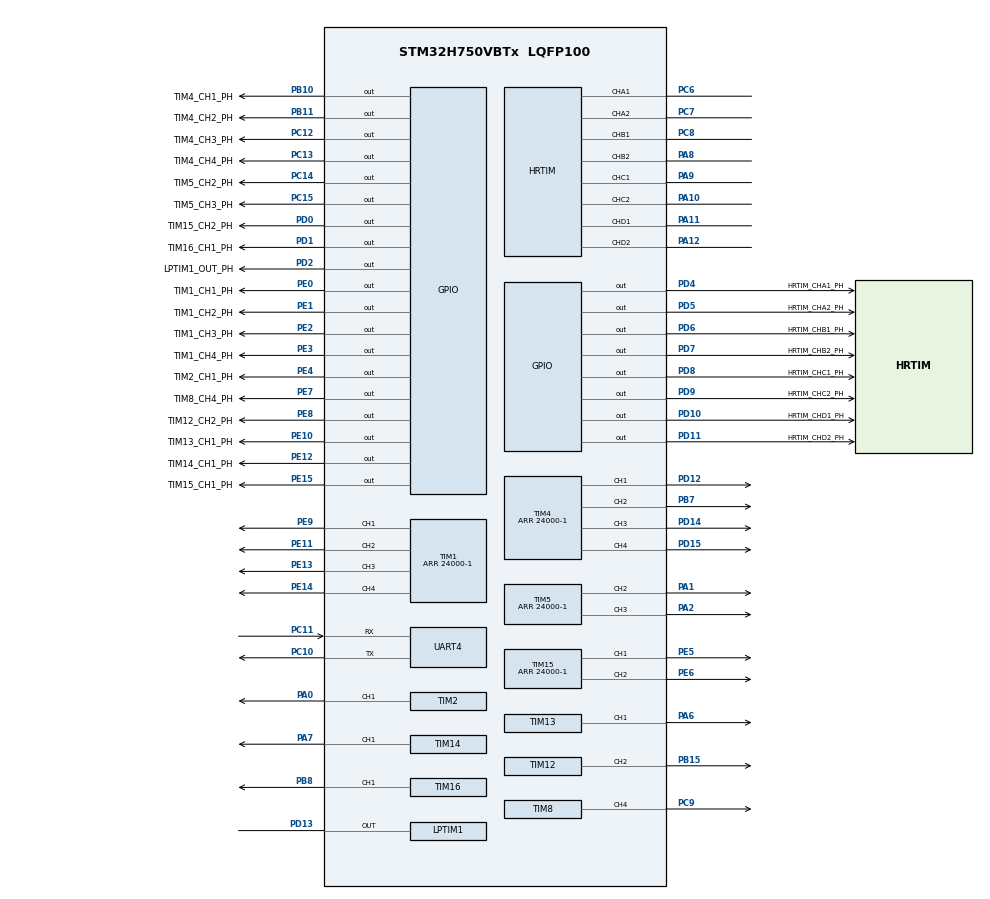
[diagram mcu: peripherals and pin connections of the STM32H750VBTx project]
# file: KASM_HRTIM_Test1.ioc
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CORTEX_M7.default_mode_Activation=1
HRTIM.CaptureUnit1-Output_TA1TA2=__NULL
HRTIM.CompareUnit1-Output_TA1TA2=HRTIM_COMPAREUNIT_1
HRTIM.CompareUnit1-Output_TB1TB2=HRTIM_COMPAREUNIT_1
HRTIM.CompareUnit1-Output_TC1TC2=HRTIM_COMPAREUNIT_1
HRTIM.CompareUnit1-Output_TD1TD2=HRTIM_COMPAREUNIT_1
HRTIM.CompareUnit2-Output_TA1TA2=HRTIM_COMPAREUNIT_2
HRTIM.CompareUnit2-Output_TB1TB2=HRTIM_COMPAREUNIT_2
HRTIM.CompareUnit2-Output_TC1TC2=HRTIM_COMPAREUNIT_2
HRTIM.CompareUnit2-Output_TD1TD2=HRTIM_COMPAREUNIT_2
HRTIM.CompareValue1-Output_TA1TA2=0x00005A00/2
HRTIM.CompareValue1-Output_TB1TB2=0x00005A00/2
HRTIM.CompareValue1-Output_TC1TC2=0x00005A00/2
HRTIM.CompareValue1-Output_TD1TD2=0x00005A00/2
HRTIM.CompareValue2-Output_TA1TA2=0x00005A00/2
HRTIM.CompareValue2-Output_TB1TB2=0x00005A00/2
HRTIM.CompareValue2-Output_TC1TC2=0x00005A00/2
HRTIM.CompareValue2-Output_TD1TD2=0x00005A00/2
HRTIM.Configuration_TA=Waveform
HRTIM.Enable=HRTIM_BURSTMODECTL_DISABLED
HRTIM.Event1-Output_TA1TA2=__NULL
HRTIM.Event_EEV1=HRTIM_EVENT_1
HRTIM.Event_EEV2=__NULL
HRTIM.HalfModeEnable-Output_TA1TA2=HRTIM_HALFMODE_DISABLED
HRTIM.NumberResetSource1-Output_TA1TA2=1
HRTIM.NumberResetSource1-Output_TB1TB2=1
HRTIM.NumberResetSource1-Output_TC1TC2=1
HRTIM.NumberResetSource1-Output_TD1TD2=1
HRTIM.NumberResetSource2_TA=1
HRTIM.NumberResetSource2_TB=1
HRTIM.NumberResetSource2_TC=1
HRTIM.NumberResetSource2_TD=1
HRTIM.NumberResetTrigger-Output_TA1TA2=1
HRTIM.NumberResetTrigger-Output_TB1TB2=1
HRTIM.NumberResetTrigger-Output_TC1TC2=1
HRTIM.NumberResetTrigger-Output_TD1TD2=1
HRTIM.NumberSetSource1-Output_TA1TA2=2
HRTIM.NumberSetSource1-Output_TB1TB2=2
HRTIM.NumberSetSource1-Output_TC1TC2=2
HRTIM.NumberSetSource1-Output_TD1TD2=2
HRTIM.NumberSetSource2_TA=2
HRTIM.NumberSetSource2_TB=2
HRTIM.NumberSetSource2_TC=2
HRTIM.NumberSetSource2_TD=2
HRTIM.NumberUpdateTrigger-Output_TA1TA2=0
HRTIM.Periode_TA=24000-1
HRTIM.Periode_TB=24000-1
HRTIM.Periode_TC=24000-1
HRTIM.Periode_TD=24000-1
HRTIM.Polarity1-Output_TA1TA2=HRTIM_OUTPUTPOLARITY_HIGH
HRTIM.PreloadEnable-Output_TA1TA2=HRTIM_PRELOAD_ENABLED
HRTIM.PreloadEnable-Output_TB1TB2=HRTIM_PRELOAD_ENABLED
HRTIM.PreloadEnable-Output_TC1TC2=HRTIM_PRELOAD_ENABLED
HRTIM.PreloadEnable-Output_TD1TD2=HRTIM_PRELOAD_ENABLED
HRTIM.PrescalerRatio_TA=HRTIM_PRESCALERRATIO_DIV1
HRTIM.PushPull-Output_TA1TA2=HRTIM_TIMPUSHPULLMODE_DISABLED
HRTIM.PushPull-Output_TB1TB2=HRTIM_TIMPUSHPULLMODE_DISABLED
HRTIM.RepetitionUpdate-Output_TA1TA2=HRTIM_UPDATEONREPETITION_DISABLED
HRTIM.ResetOutput1_Source1-Output_TA1TA2=HRTIM_OUTPUTRESET_TIMCMP1
HRTIM.ResetOutput1_Source1-Output_TB1TB2=HRTIM_OUTPUTRESET_TIMCMP1
HRTIM.ResetOutput1_Source1-Output_TC1TC2=HRTIM_OUTPUTRESET_TIMCMP1
HRTIM.ResetOutput1_Source1-Output_TD1TD2=HRTIM_OUTPUTRESET_TIMCMP1
HRTIM.ResetOutput2_Source1-Output_TA1TA2=HRTIM_OUTPUTRESET_TIMCMP2
HRTIM.ResetOutput2_Source1-Output_TB1TB2=HRTIM_OUTPUTRESET_TIMCMP2
HRTIM.ResetOutput2_Source1-Output_TC1TC2=HRTIM_OUTPUTRESET_TIMCMP2
HRTIM.ResetOutput2_Source1-Output_TD1TD2=HRTIM_OUTPUTRESET_TIMCMP2
HRTIM.ResetTrigger1-Output_TA1TA2=HRTIM_TIMRESETTRIGGER_EEV_1
HRTIM.ResetTrigger1-Output_TB1TB2=HRTIM_TIMRESETTRIGGER_EEV_1
HRTIM.ResetTrigger1-Output_TC1TC2=HRTIM_TIMRESETTRIGGER_EEV_1
HRTIM.ResetTrigger1-Output_TD1TD2=HRTIM_TIMRESETTRIGGER_EEV_1
HRTIM.ResetUpdate-Output_TA1TA2=HRTIM_TIMUPDATEONRESET_ENABLED
HRTIM.ResetUpdate-Output_TB1TB2=HRTIM_TIMUPDATEONRESET_ENABLED
HRTIM.ResetUpdate-Output_TC1TC2=HRTIM_TIMUPDATEONRESET_ENABLED
HRTIM.ResetUpdate-Output_TD1TD2=HRTIM_TIMUPDATEONRESET_ENABLED
HRTIM.Sensitivity_EEV1=HRTIM_EVENTSENSITIVITY_RISINGEDGE
HRTIM.SetOutput1_Source1-Output_TA1TA2=HRTIM_OUTPUTSET_EEV_1
HRTIM.SetOutput1_Source1-Output_TB1TB2=HRTIM_OUTPUTSET_EEV_1
HRTIM.SetOutput1_Source1-Output_TC1TC2=HRTIM_OUTPUTSET_EEV_1
HRTIM.SetOutput1_Source1-Output_TD1TD2=HRTIM_OUTPUTSET_EEV_1
HRTIM.SetOutput1_Source2-Output_TA1TA2=HRTIM_OUTPUTSET_TIMPER
HRTIM.SetOutput1_Source2-Output_TB1TB2=HRTIM_OUTPUTSET_TIMPER
HRTIM.SetOutput1_Source2-Output_TC1TC2=HRTIM_OUTPUTSET_TIMPER
HRTIM.SetOutput1_Source2-Output_TD1TD2=HRTIM_OUTPUTSET_TIMPER
HRTIM.SetOutput2_Source1-Output_TA1TA2=HRTIM_OUTPUTSET_EEV_1
HRTIM.SetOutput2_Source1-Output_TB1TB2=HRTIM_OUTPUTSET_EEV_1
HRTIM.SetOutput2_Source1-Output_TC1TC2=HRTIM_OUTPUTSET_EEV_1
HRTIM.SetOutput2_Source1-Output_TD1TD2=HRTIM_OUTPUTSET_EEV_1
HRTIM.SetOutput2_Source2-Output_TA1TA2=HRTIM_OUTPUTSET_TIMPER
HRTIM.SetOutput2_Source2-Output_TB1TB2=HRTIM_OUTPUTSET_TIMPER
HRTIM.SetOutput2_Source2-Output_TC1TC2=HRTIM_OUTPUTSET_TIMPER
HRTIM.SetOutput2_Source2-Output_TD1TD2=HRTIM_OUTPUTSET_TIMPER
HRTIM.Source_EEV1=HRTIM_EVENTSRC_3
HRTIM.StartOnSync-Output_TA1TA2=HRTIM_SYNCSTART_DISABLED
HRTIM.SyncOptions=HRTIM_SYNCOPTION_NONE
LPTIM1.OutputPolarity=LPTIM_OUTPUTPOLARITY_LOW
LPTIM1.TriggerSource=LPTIM_TRIGSOURCE_SOFTWARE
LPTIM1.UpdateMode=LPTIM_UPDATE_IMMEDIATE
Mcu.Family=STM32H7
Mcu.Name=STM32H750VBTx
Mcu.Package=LQFP100
NVIC.LPTIM1_IRQn=true\:0\:0\:false\:false\:true\:true\:true\:true
NVIC.PriorityGroup=NVIC_PRIORITYGROUP_4
NVIC.TIM15_IRQn=true\:0\:0\:false\:false\:true\:true\:true\:true
NVIC.TIM16_IRQn=true\:0\:0\:false\:false\:true\:true\:true\:true
NVIC.TIM1_UP_IRQn=true\:0\:0\:false\:false\:true\:true\:true\:true
NVIC.TIM2_IRQn=true\:0\:0\:false\:false\:true\:true\:true\:true
NVIC.TIM4_IRQn=true\:0\:0\:false\:false\:true\:true\:true\:true
NVIC.TIM5_IRQn=true\:0\:0\:false\:false\:true\:true\:true\:true
NVIC.TIM8_BRK_TIM12_IRQn=true\:0\:0\:false\:false\:true\:true\:true\:true
NVIC.TIM8_TRG_COM_TIM14_IRQn=true\:0\:0\:false\:false\:true\:true\:true\:true
NVIC.TIM8_UP_TIM13_IRQn=true\:0\:0\:false\:false\:true\:true\:true\:true
NVIC.UART4_IRQn=true\:0\:0\:false\:false\:true\:true\:true\:true
PA0.Signal=S_TIM2_CH1_ETR
PA1.Signal=S_TIM5_CH2
PA10.Mode=Output_TC1TC2
PA10.Signal=HRTIM_CHC2
PA11.Mode=Output_TD1TD2
PA11.Signal=HRTIM_CHD1
PA12.Mode=Output_TD1TD2
PA12.Signal=HRTIM_CHD2
PA2.Signal=S_TIM5_CH3
PA6.Signal=S_TIM13_CH1
PA7.Signal=S_TIM14_CH1
PA8.Mode=Output_TB1TB2
PA8.Signal=HRTIM_CHB2
PA9.Mode=Output_TC1TC2
PA9.Signal=HRTIM_CHC1
PB10.GPIO_Label=TIM4_CH1_PH
PB10.Signal=GPIO_Output
PB11.GPIO_Label=TIM4_CH2_PH
PB11.Signal=GPIO_Output
PB15.Signal=S_TIM12_CH2
PB7.Signal=S_TIM4_CH2
PB8.Signal=S_TIM16_CH1
PC10.Mode=Asynchronous
PC10.Signal=UART4_TX
PC11.Mode=Asynchronous
PC11.Signal=UART4_RX
PC12.GPIO_Label=TIM4_CH3_PH
PC12.Signal=GPIO_Output
PC13.GPIO_Label=TIM4_CH4_PH
PC13.Signal=GPIO_Output
PC14-OSC32_IN\ (OSC32_IN).GPIO_Label=TIM5_CH2_PH
PC14-OSC32_IN\ (OSC32_IN).Signal=GPIO_Output
PC15-OSC32_OUT\ (OSC32_OUT).GPIO_Label=TIM5_CH3_PH
PC15-OSC32_OUT\ (OSC32_OUT).Signal=GPIO_Output
PC6.GPIO_Speed_High_Default=GPIO_SPEED_FREQ_VERY_HIGH
PC6.Mode=Output_TA1TA2
PC6.Signal=HRTIM_CHA1
PC7.GPIO_Speed_High_Default=GPIO_SPEED_FREQ_VERY_HIGH
PC7.Mode=Output_TA1TA2
PC7.Signal=HRTIM_CHA2
PC8.Mode=Output_TB1TB2
PC8.Signal=HRTIM_CHB1
PC9.Signal=S_TIM8_CH4
PD0.GPIO_Label=TIM15_CH2_PH
PD0.Signal=GPIO_Output
PD1.GPIO_Label=TIM16_CH1_PH
PD1.Signal=GPIO_Output
PD10.GPIO_Label=HRTIM_CHD1_PH
PD10.Signal=GPIO_Output
PD11.GPIO_Label=HRTIM_CHD2_PH
PD11.Signal=GPIO_Output
PD12.Signal=S_TIM4_CH1
PD13.Mode=WaveformGeneration
PD13.Signal=LPTIM1_OUT
PD14.Signal=S_TIM4_CH3
PD15.Signal=S_TIM4_CH4
PD2.GPIO_Label=LPTIM1_OUT_PH
PD2.Signal=GPIO_Output
PD4.GPIO_Label=HRTIM_CHA1_PH
PD4.Signal=GPIO_Output
PD5.GPIO_Label=HRTIM_CHA2_PH
PD5.Signal=GPIO_Output
PD6.GPIO_Label=HRTIM_CHB1_PH
PD6.Signal=GPIO_Output
PD7.GPIO_Label=HRTIM_CHB2_PH
PD7.Signal=GPIO_Output
PD8.GPIO_Label=HRTIM_CHC1_PH
PD8.Signal=GPIO_Output
PD9.GPIO_Label=HRTIM_CHC2_PH
PD9.Signal=GPIO_Output
PE0.GPIO_Label=TIM1_CH1_PH
PE0.Signal=GPIO_Output
PE1.GPIO_Label=TIM1_CH2_PH
PE1.Signal=GPIO_Output
PE10.GPIO_Label=TIM13_CH1_PH
PE10.Signal=GPIO_Output
PE11.Signal=S_TIM1_CH2
PE12.GPIO_Label=TIM14_CH1_PH
PE12.Signal=GPIO_Output
PE13.Signal=S_TIM1_CH3
PE14.Signal=S_TIM1_CH4
PE15.GPIO_Label=TIM15_CH1_PH
PE15.Signal=GPIO_Output
PE2.GPIO_Label=TIM1_CH3_PH
PE2.Signal=GPIO_Output
PE3.GPIO_Label=TIM1_CH4_PH
PE3.Signal=GPIO_Output
PE4.GPIO_Label=TIM2_CH1_PH
PE4.Signal=GPIO_Output
PE5.Signal=S_TIM15_CH1
PE6.Signal=S_TIM15_CH2
PE7.GPIO_Label=TIM8_CH4_PH
PE7.Signal=GPIO_Output
PE8.GPIO_Label=TIM12_CH2_PH
PE8.Signal=GPIO_Output
PE9.Signal=S_TIM1_CH1
PH0-OSC_IN\ (PH0).Mode=HSE-External-Oscillator
PH0-OSC_IN\ (PH0).Signal=RCC_OSC_IN
PH1-OSC_OUT\ (PH1).Mode=HSE-External-Oscillator
PH1-OSC_OUT\ (PH1).Signal=RCC_OSC_OUT
ProjectManager.HeapSize=0x200
ProjectManager.StackSize=0x400
ProjectManager.TargetToolchain=STM32CubeIDE
RCC.ADCFreq_Value=48375000
RCC.APB1Freq_Value=120000000
RCC.APB2Freq_Value=120000000
RCC.APB3Freq_Value=120000000
RCC.APB4Freq_Value=120000000
RCC.CortexFreq_Value=480000000
RCC.D1PPRE=RCC_APB3_DIV2
RCC.D2PPRE1=RCC_APB1_DIV2
RCC.D2PPRE2=RCC_APB2_DIV2
RCC.D3PPRE=RCC_APB4_DIV2
RCC.DIVM1=2
RCC.DIVN1=80
RCC.HCLKFreq_Value=240000000
RCC.HPRE=RCC_HCLK_DIV2
RCC.HSE_VALUE=24000000
RCC.PLLSourceVirtual=RCC_PLLSOURCE_HSE
RCC.RCC_TIM_PRescaler_Selection=RCC_TIMPRES_DESACTIVATED
RCC.SYSCLKFreq_VALUE=480000000
RCC.SYSCLKSource=RCC_SYSCLKSOURCE_PLLCLK
RCC.USBFreq_Value=480000000
SH.S_TIM12_CH2.0=TIM12_CH2,PWM Generation2 CH2
SH.S_TIM13_CH1.0=TIM13_CH1,PWM Generation1 CH1
SH.S_TIM14_CH1.0=TIM14_CH1,PWM Generation1 CH1
SH.S_TIM15_CH1.0=TIM15_CH1,PWM Generation1 CH1
SH.S_TIM15_CH2.0=TIM15_CH2,PWM Generation2 CH2
SH.S_TIM16_CH1.0=TIM16_CH1,PWM Generation1 CH1
SH.S_TIM1_CH1.0=TIM1_CH1,PWM Generation1 CH1
SH.S_TIM1_CH2.0=TIM1_CH2,PWM Generation2 CH2
SH.S_TIM1_CH3.0=TIM1_CH3,PWM Generation3 CH3
SH.S_TIM1_CH4.0=TIM1_CH4,PWM Generation4 CH4
SH.S_TIM2_CH1_ETR.0=TIM2_CH1,PWM Generation1 CH1
SH.S_TIM4_CH1.0=TIM4_CH1,PWM Generation1 CH1
SH.S_TIM4_CH2.0=TIM4_CH2,PWM Generation2 CH2
SH.S_TIM4_CH3.0=TIM4_CH3,PWM Generation3 CH3
SH.S_TIM4_CH4.0=TIM4_CH4,PWM Generation4 CH4
SH.S_TIM5_CH2.0=TIM5_CH2,PWM Generation2 CH2
SH.S_TIM5_CH3.0=TIM5_CH3,PWM Generation3 CH3
SH.S_TIM8_CH4.0=TIM8_CH4,PWM Generation4 CH4
TIM1.AutoReloadPreload=TIM_AUTORELOAD_PRELOAD_ENABLE
TIM1.Channel-PWM\ Generation1\ CH1=TIM_CHANNEL_1
TIM1.Channel-PWM\ Generation2\ CH2=TIM_CHANNEL_2
TIM1.Channel-PWM\ Generation3\ CH3=TIM_CHANNEL_3
TIM1.Channel-PWM\ Generation4\ CH4=TIM_CHANNEL_4
TIM1.Period=24000-1
TIM1.TIM_MasterOutputTrigger=TIM_TRGO_UPDATE
TIM1.TIM_MasterSlaveMode=TIM_MASTERSLAVEMODE_DISABLE
TIM12.AutoReloadPreload=TIM_AUTORELOAD_PRELOAD_ENABLE
TIM12.Channel-PWM\ Generation2\ CH2=TIM_CHANNEL_2
TIM12.Period=24000-1
TIM13.AutoReloadPreload=TIM_AUTORELOAD_PRELOAD_ENABLE
TIM13.Channel=TIM_CHANNEL_1
TIM13.Period=24000-1
TIM14.AutoReloadPreload=TIM_AUTORELOAD_PRELOAD_ENABLE
TIM14.Channel=TIM_CHANNEL_1
TIM14.Period=24000-1
TIM15.AutoReloadPreload=TIM_AUTORELOAD_PRELOAD_ENABLE
TIM15.Channel-PWM\ Generation1\ CH1=TIM_CHANNEL_1
TIM15.Channel-PWM\ Generation2\ CH2=TIM_CHANNEL_2
TIM15.Period=24000-1
TIM16.AutoReloadPreload=TIM_AUTORELOAD_PRELOAD_ENABLE
TIM16.Channel=TIM_CHANNEL_1
TIM16.Period=24000-1
TIM2.AutoReloadPreload=TIM_AUTORELOAD_PRELOAD_ENABLE
TIM2.Channel-PWM\ Generation1\ CH1=TIM_CHANNEL_1
TIM2.Period=24000-1
TIM2.TIM_MasterOutputTrigger=TIM_TRGO_RESET
TIM2.TIM_MasterSlaveMode=TIM_MASTERSLAVEMODE_DISABLE
TIM4.AutoReloadPreload=TIM_AUTORELOAD_PRELOAD_ENABLE
TIM4.Channel-PWM\ Generation1\ CH1=TIM_CHANNEL_1
TIM4.Channel-PWM\ Generation2\ CH2=TIM_CHANNEL_2
TIM4.Channel-PWM\ Generation3\ CH3=TIM_CHANNEL_3
TIM4.Channel-PWM\ Generation4\ CH4=TIM_CHANNEL_4
TIM4.Period=24000-1
TIM5.AutoReloadPreload=TIM_AUTORELOAD_PRELOAD_ENABLE
TIM5.Channel-PWM\ Generation2\ CH2=TIM_CHANNEL_2
TIM5.Channel-PWM\ Generation3\ CH3=TIM_CHANNEL_3
TIM5.Period=24000-1
TIM8.AutoReloadPreload=TIM_AUTORELOAD_PRELOAD_ENABLE
TIM8.Channel-PWM\ Generation4\ CH4=TIM_CHANNEL_4
TIM8.Period=24000-1
UART4.FIFOMode=FIFOMODE_DISABLE
VP_LPTIM1_VS_LPTIM_counterModeInternalClock.Mode=Counts__internal_clock_event_00
VP_TIM12_VS_ClockSourceINT.Mode=Internal
VP_TIM13_VS_ClockSourceINT.Mode=Enable_Timer
VP_TIM14_VS_ClockSourceINT.Mode=Enable_Timer
VP_TIM15_VS_ClockSourceINT.Mode=Internal
VP_TIM16_VS_ClockSourceINT.Mode=Enable_Timer
VP_TIM1_VS_ClockSourceINT.Mode=Internal
VP_TIM2_VS_ClockSourceINT.Mode=Internal
VP_TIM4_VS_ClockSourceINT.Mode=Internal
VP_TIM5_VS_ClockSourceINT.Mode=Internal
VP_TIM8_VS_ClockSourceINT.Mode=Internal
board=custom

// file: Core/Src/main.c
<<<<<<< HEAD
/* USER CODE BEGIN Header */
/**
  ******************************************************************************
  * @file           : main.c
  * @brief          : Main program body
  ******************************************************************************
  * @attention
  *
  * Copyright (c) 2024 STMicroelectronics.
  * All rights reserved.
  *
  * This software is licensed under terms that can be found in the LICENSE file
  * in the root directory of this software component.
  * If no LICENSE file comes with this software, it is provided AS-IS.
  *
  ******************************************************************************
  */
/* USER CODE END Header */
#include "main.h"

/* USER CODE BEGIN Includes */
#include <math.h>
#include <stdio.h>
/* USER CODE END Includes */

/* USER CODE BEGIN PD */

//Converts timer ticks to time scaling factor
#define PERIOD_SCALE (1.0/24000)
#define TICK_SCALE (1.0/240000000)

//Circular buffer characteristics
#define BUFFER_LENGTH 2048
#define MESSAGE_LENGTH 128

//Parameters for sorting/storing actuator commands
#define CMD_LENGTH 27*2
#define NUM_ACTUATORS 27
/* USER CODE END PD */

HRTIM_HandleTypeDef hhrtim;

LPTIM_HandleTypeDef hlptim1;

TIM_HandleTypeDef htim1;
TIM_HandleTypeDef htim2;
TIM_HandleTypeDef htim4;
TIM_HandleTypeDef htim5;
TIM_HandleTypeDef htim8;
TIM_HandleTypeDef htim12;
TIM_HandleTypeDef htim13;
TIM_HandleTypeDef htim14;
TIM_HandleTypeDef htim15;
TIM_HandleTypeDef htim16;

/* USER CODE BEGIN PV */

static const double VSS = 1.8; // fixed by PCB design
char msg[80];
int msg_length;
uint8_t ctrl_tmr_expired = FALSE; //controller update flag
static double ref=0;// reference (input) for control loop
static double sine_vals[SIN_PERIOD] = {0};
int data_ready = FALSE;
uint8_t recvd_byte = 0;

/*Use for checking initialization times over UART
static long long int sys_timer = 0;
char message[64] = {'\0'};

//Counter for UART Output in Time-Scale
	static long int period_ticks = 0;
	char buffer[64];

	float read_TIM1_sec(){
		float time = 0;
		time = period_ticks * PERIOD_SCALE + TIM1->CNT * TICK_SCALE;
		return time;
	}

//Counter for UART Output in clock ticks
		uint64_t read_TIM1() {
		//return TIM1->CNT;
		 return TIM1->CNT + sys_timer;
	  }
*/

//Circular Buffer
struct circular_buffer {
	int read_index;
	int write_index;
	int size;
	unsigned char data[BUFFER_LENGTH];
};

// Circular UART RX buffer
struct circular_buffer rx_buffer;
struct circular_buffer *rxp = &rx_buffer;

//static int8_t rx_collision = FALSE;
static int8_t reading_rx_buffer = FALSE;

//Buffer storing elements from circular buffer
static uint8_t cmd_bytes[BUFFER_LENGTH]= {0};
static int8_t index = 0;

//Flag to indicate a command is ready
static uint8_t cmd_ready = FALSE;

//output channels enum
enum output{T1C1 = 0,
			T1C2,
			T1C3,
			T1C4,
			T2C1,
			T4C1,
			T4C2,
			T4C3,
			T4C4,
			T5C2,
			T5C3,
			T8C4,
			T12C2,
			T13C1,
			T14C1,
			T15C1,
			T15C2,
			T16C1,
			HRA1,
			HRA2,
			HRB1,
			HRB2,
			HRC1,
			HRC2,
			HRD1,
			HRD2,
			LPTIM
} channel;

// Array to store the command reference positions
static int16_t cmd_ref[NUM_ACTUATORS] = {0};

//State meachine elements
typedef enum UART_receive_state{
	startByte1,
	startByte2,
	storeMessage,
	endByte1,
	endByte2,
	messageReady
}state;

// Command string delimiters
uint8_t start_bytes[2] = {1, 128};
uint8_t end_bytes[2] = {255, 127};

/* USER CODE END PV */

void SystemClock_Config(void);
static void MPU_Config(void);
static void MX_GPIO_Init(void);
static void MX_TIM1_Init(void);
static void MX_TIM2_Init(void);
static void MX_TIM4_Init(void);
static void MX_TIM5_Init(void);
static void MX_TIM8_Init(void);
static void MX_TIM12_Init(void);
static void MX_TIM13_Init(void);
static void MX_TIM14_Init(void);
static void MX_TIM15_Init(void);
static void MX_TIM16_Init(void);
static void MX_HRTIM_Init(void);
static void MX_LPTIM1_Init(void);
static void MX_UART4_Init(void);
/* USER CODE BEGIN PFP */
static void control_update(double ref);
static uint16_t calc_dutycycle(uint16_t v_in, double vss);
static void gen_sine(void);
void UART_update();
void command_update();
static void run_state_machine(uint8_t byte);
static void init_buffer(struct circular_buffer *buf);
static int8_t is_buffer_empty(struct circular_buffer *buf);
static int8_t is_buffer_full(struct circular_buffer *buf);
static int8_t write_buffer(struct circular_buffer *buf, unsigned char c);
static unsigned char read_from_buffer(struct circular_buffer *buf);
static int get_num_elements(struct circular_buffer *buf);
/* USER CODE END PFP */

int main(void)
{

  /* MPU Configuration--------------------------------------------------------*/
  MPU_Config();

  /* MCU Configuration--------------------------------------------------------*/

  /* Reset of all peripherals, Initializes the Flash interface and the Systick. */
  HAL_Init();

  /* Configure the system clock */
  SystemClock_Config();

  /* Initialize all configured peripherals */
  MX_GPIO_Init();
  MX_TIM1_Init();
  MX_TIM2_Init();
  MX_TIM4_Init();
  MX_TIM5_Init();
  MX_TIM8_Init();
  MX_TIM12_Init();
  MX_TIM13_Init();
  MX_TIM14_Init();
  MX_TIM15_Init();
  MX_TIM16_Init();
  MX_HRTIM_Init();
  MX_LPTIM1_Init();
  MX_UART4_Init();
  /* USER CODE BEGIN 2 */

  //Timer 1
  HAL_TIM_Base_Start_IT(&htim1);
  HAL_TIM_PWM_Start(&htim1, TIM_CHANNEL_1);    //Starts the PWM on each of the desired channels
  HAL_TIM_PWM_Start(&htim1, TIM_CHANNEL_2);
  HAL_TIM_PWM_Start(&htim1, TIM_CHANNEL_3);
  HAL_TIM_PWM_Start(&htim1, TIM_CHANNEL_4);
  HAL_GPIO_WritePin(TIM1_CH1_PH_GPIO_Port, TIM1_CH1_PH_Pin, GPIO_PIN_SET);   //Sets the pin to 1
  HAL_GPIO_WritePin(TIM1_CH2_PH_GPIO_Port, TIM1_CH2_PH_Pin, GPIO_PIN_SET);
  HAL_GPIO_WritePin(TIM1_CH3_PH_GPIO_Port, TIM1_CH3_PH_Pin, GPIO_PIN_SET);
  HAL_GPIO_WritePin(TIM1_CH4_PH_GPIO_Port, TIM1_CH4_PH_Pin, GPIO_PIN_SET);

  	  	  	/* Example of how to check Initialization time, timer count, and period counts over UART
			//Timer 1 Init. Message Over UART
			sprintf(message, "Tim1 Init: %d \n\r", read_TIM1());
			HAL_UART_Transmit(&huart4, (uint8_t*)message, sizeof(message), 100);

  	  	  	sprintf(buffer, "Tim1 sec: %e \n\r", read_TIM1_sec());
  			HAL_UART_Transmit(&huart4, (uint8_t*)buffer, sizeof(buffer), HAL_MAX_DELAY);
  			sprintf(buffer, "Tim1 Cnt: %d \n\r", TIM1->CNT);
  			HAL_UART_Transmit(&huart4, (uint8_t*)buffer, sizeof(buffer), HAL_MAX_DELAY);
  			sprintf(buffer, "Per Cnt: %d \n\r", period_ticks);
  			HAL_UART_Transmit(&huart4, (uint8_t*)buffer, sizeof(buffer), HAL_MAX_DELAY);
  			//End UART Transmit
  			 *
  			 */
  //End Timer 1

  //Timer 2
  HAL_TIM_Base_Start_IT(&htim2);
  HAL_TIM_PWM_Start(&htim2, TIM_CHANNEL_1);
  HAL_GPIO_WritePin(TIM2_CH1_PH_GPIO_Port, TIM2_CH1_PH_Pin, GPIO_PIN_SET);
  //End Timer 2

  //Timer 4
  HAL_TIM_Base_Start_IT(&htim4);
  HAL_TIM_PWM_Start(&htim4, TIM_CHANNEL_1);
  HAL_TIM_PWM_Start(&htim4, TIM_CHANNEL_2);
  HAL_TIM_PWM_Start(&htim4, TIM_CHANNEL_3);
  HAL_TIM_PWM_Start(&htim4, TIM_CHANNEL_4);
  HAL_GPIO_WritePin(TIM4_CH1_PH_GPIO_Port, TIM4_CH1_PH_Pin, GPIO_PIN_SET);
  HAL_GPIO_WritePin(TIM4_CH2_PH_GPIO_Port, TIM4_CH2_PH_Pin, GPIO_PIN_SET);
  HAL_GPIO_WritePin(TIM4_CH3_PH_GPIO_Port, TIM4_CH3_PH_Pin, GPIO_PIN_SET);
  HAL_GPIO_WritePin(TIM4_CH4_PH_GPIO_Port, TIM4_CH4_PH_Pin, GPIO_PIN_SET);
  //End Timer 4

  //Timer 5
  HAL_TIM_Base_Start_IT(&htim5);
  HAL_TIM_PWM_Start(&htim5, TIM_CHANNEL_2);
  HAL_TIM_PWM_Start(&htim5, TIM_CHANNEL_3);
  HAL_GPIO_WritePin(TIM5_CH2_PH_GPIO_Port, TIM5_CH2_PH_Pin, GPIO_PIN_SET);
  HAL_GPIO_WritePin(TIM5_CH3_PH_GPIO_Port, TIM5_CH3_PH_Pin, GPIO_PIN_SET);
  //End Timer 5

  //Timer 8
  HAL_TIM_Base_Start_IT(&htim8);
  HAL_TIM_PWM_Start(&htim8, TIM_CHANNEL_4);
  HAL_GPIO_WritePin(TIM8_CH4_PH_GPIO_Port, TIM8_CH4_PH_Pin, GPIO_PIN_SET);
  //End Timer 8

  //Timer 12
  HAL_TIM_Base_Start_IT(&htim12);
  HAL_TIM_PWM_Start(&htim12, TIM_CHANNEL_2);
  HAL_GPIO_WritePin(TIM12_CH2_PH_GPIO_Port, TIM12_CH2_PH_Pin, GPIO_PIN_SET);
  //End Timer 12

  //Timer 13
  HAL_TIM_Base_Start_IT(&htim13);
  HAL_TIM_PWM_Start(&htim13, TIM_CHANNEL_1);
  HAL_GPIO_WritePin(TIM13_CH1_PH_GPIO_Port, TIM13_CH1_PH_Pin, GPIO_PIN_SET);
  //End Timer 13

  //Timer 14
  HAL_TIM_Base_Start_IT(&htim14);
  HAL_TIM_PWM_Start(&htim14, TIM_CHANNEL_1);
  HAL_GPIO_WritePin(TIM14_CH1_PH_GPIO_Port, TIM14_CH1_PH_Pin, GPIO_PIN_SET);
  //End Timer 14

  //Timer 15
  HAL_TIM_Base_Start_IT(&htim15);
  HAL_TIM_PWM_Start(&htim15, TIM_CHANNEL_1);
  HAL_TIM_PWM_Start(&htim15, TIM_CHANNEL_2);
  HAL_GPIO_WritePin(TIM15_CH1_PH_GPIO_Port, TIM15_CH1_PH_Pin, GPIO_PIN_SET);
  HAL_GPIO_WritePin(TIM15_CH2_PH_GPIO_Port, TIM15_CH2_PH_Pin, GPIO_PIN_SET);
  //End Timer 15

  //Timer 16
  HAL_TIM_Base_Start_IT(&htim16);
  HAL_TIM_PWM_Start(&htim16, TIM_CHANNEL_1);
  HAL_GPIO_WritePin(TIM16_CH1_PH_GPIO_Port, TIM16_CH1_PH_Pin, GPIO_PIN_SET);
  //End Timer 16

  //HRTIM CODE GOES HERE *******
     // Enable output
  HRTIM1->sCommonRegs.OENR = HRTIM_OENR_TA1OEN + HRTIM_OENR_TA2OEN +
     	 	HRTIM_OENR_TB1OEN + HRTIM_OENR_TB2OEN + HRTIM_OENR_TC1OEN + HRTIM_OENR_TC2OEN + HRTIM_OENR_TD1OEN + HRTIM_OENR_TD2OEN;
     //Start Timer
  HRTIM1->sMasterRegs.MCR = HRTIM_MCR_TACEN + HRTIM_MCR_TBCEN + HRTIM_MCR_TCCEN + HRTIM_MCR_TDCEN;
  //END HRTIM CODE

	//Low-Power Timer
  HAL_LPTIM_Counter_Start_IT(&hlptim1, LPTIM_ARR_ARR);
  HAL_LPTIM_PWM_Start(&hlptim1, LPTIM_ARR_ARR, LPTIM_CMP_CMP);
  HAL_GPIO_WritePin(LPTIM1_OUT_PH_GPIO_Port, LPTIM1_OUT_PH_Pin, GPIO_PIN_SET);
  LPTIM1->ARR = (12000 - 1);
  //End Low Power Timer

  //Timer Synchronization
  TIM1->CNT = 0;
  TIM2->CNT = 0;
  TIM4->CNT = 0;
  TIM5->CNT = 0;
  TIM8->CNT = 0;
  TIM12->CNT = 0;
  TIM13->CNT = 0;
  TIM14->CNT = 0;
  TIM15->CNT = 0;
  TIM16->CNT = 0;
  LPTIM1->CNT = 0;

  // used to send sine wave output to the actuators if so desired
  gen_sine();

  /* USER CODE END 2 */

  /* Infinite loop */
  /* USER CODE BEGIN WHILE */
  init_buffer(rxp);
  data_ready = FALSE;
//  HAL_UART_Receive_IT(&huart4, rx_buff, sizeof(rx_buff));

  while (1)
  {
	  if(ctrl_tmr_expired == TRUE) control_update(ref); //Sets flag for timer interrupt
	  if(data_ready == TRUE) UART_update(); //Sets flag when a message is received
	  if(cmd_ready == TRUE) command_update(); //Sets flag once message is ready to send

    /* USER CODE END WHILE */

  }
}

void SystemClock_Config(void)
{
  RCC_OscInitTypeDef RCC_OscInitStruct = {0};
  RCC_ClkInitTypeDef RCC_ClkInitStruct = {0};

  /** Supply configuration update enable
  */
  HAL_PWREx_ConfigSupply(PWR_LDO_SUPPLY);

  /** Configure the main internal regulator output voltage
  */
  __HAL_PWR_VOLTAGESCALING_CONFIG(PWR_REGULATOR_VOLTAGE_SCALE1);

  while(!__HAL_PWR_GET_FLAG(PWR_FLAG_VOSRDY)) {}

  __HAL_RCC_SYSCFG_CLK_ENABLE();
  __HAL_PWR_VOLTAGESCALING_CONFIG(PWR_REGULATOR_VOLTAGE_SCALE0);

  while(!__HAL_PWR_GET_FLAG(PWR_FLAG_VOSRDY)) {}

  /** Initializes the RCC Oscillators according to the specified parameters
  * in the RCC_OscInitTypeDef structure.
  */
  RCC_OscInitStruct.OscillatorType = RCC_OSCILLATORTYPE_HSE;
  RCC_OscInitStruct.HSEState = RCC_HSE_ON;
  RCC_OscInitStruct.PLL.PLLState = RCC_PLL_ON;
  RCC_OscInitStruct.PLL.PLLSource = RCC_PLLSOURCE_HSE;
  RCC_OscInitStruct.PLL.PLLM = 2;
  RCC_OscInitStruct.PLL.PLLN = 80;
  RCC_OscInitStruct.PLL.PLLP = 2;
  RCC_OscInitStruct.PLL.PLLQ = 2;
  RCC_OscInitStruct.PLL.PLLR = 2;
  RCC_OscInitStruct.PLL.PLLRGE = RCC_PLL1VCIRANGE_3;
  RCC_OscInitStruct.PLL.PLLVCOSEL = RCC_PLL1VCOWIDE;
  RCC_OscInitStruct.PLL.PLLFRACN = 0;
  if (HAL_RCC_OscConfig(&RCC_OscInitStruct) != HAL_OK)
  {
    Error_Handler();
  }

  /** Initializes the CPU, AHB and APB buses clocks
  */
  RCC_ClkInitStruct.ClockType = RCC_CLOCKTYPE_HCLK|RCC_CLOCKTYPE_SYSCLK
                              |RCC_CLOCKTYPE_PCLK1|RCC_CLOCKTYPE_PCLK2
                              |RCC_CLOCKTYPE_D3PCLK1|RCC_CLOCKTYPE_D1PCLK1;
  RCC_ClkInitStruct.SYSCLKSource = RCC_SYSCLKSOURCE_PLLCLK;
  RCC_ClkInitStruct.SYSCLKDivider = RCC_SYSCLK_DIV1;
  RCC_ClkInitStruct.AHBCLKDivider = RCC_HCLK_DIV2;
  RCC_ClkInitStruct.APB3CLKDivider = RCC_APB3_DIV2;
  RCC_ClkInitStruct.APB1CLKDivider = RCC_APB1_DIV2;
  RCC_ClkInitStruct.APB2CLKDivider = RCC_APB2_DIV2;
  RCC_ClkInitStruct.APB4CLKDivider = RCC_APB4_DIV2;

  if (HAL_RCC_ClockConfig(&RCC_ClkInitStruct, FLASH_LATENCY_4) != HAL_OK)
  {
    Error_Handler();
  }
}

static void MX_HRTIM_Init(void)
{

  HRTIM_EventCfgTypeDef pEventCfg = {0};
  HRTIM_TimeBaseCfgTypeDef pTimeBaseCfg = {0};
  HRTIM_TimerCfgTypeDef pTimerCfg = {0};
  HRTIM_CompareCfgTypeDef pCompareCfg = {0};
  HRTIM_OutputCfgTypeDef pOutputCfg = {0};

  hhrtim.Instance = HRTIM1;
  hhrtim.Init.HRTIMInterruptResquests = HRTIM_IT_NONE;
  hhrtim.Init.SyncOptions = HRTIM_SYNCOPTION_NONE;
  if (HAL_HRTIM_Init(&hhrtim) != HAL_OK)
  {
    Error_Handler();
  }
  if (HAL_HRTIM_EventPrescalerConfig(&hhrtim, HRTIM_EVENTPRESCALER_DIV1) != HAL_OK)
  {
    Error_Handler();
  }
  pEventCfg.Source = HRTIM_EVENTSRC_3;
  pEventCfg.Polarity = HRTIM_EVENTPOLARITY_HIGH;
  pEventCfg.Sensitivity = HRTIM_EVENTSENSITIVITY_RISINGEDGE;
  pEventCfg.FastMode = HRTIM_EVENTFASTMODE_DISABLE;
  if (HAL_HRTIM_EventConfig(&hhrtim, HRTIM_EVENT_1, &pEventCfg) != HAL_OK)
  {
    Error_Handler();
  }
  pTimeBaseCfg.Period = 24000-1;
  pTimeBaseCfg.RepetitionCounter = 0x00;
  pTimeBaseCfg.PrescalerRatio = HRTIM_PRESCALERRATIO_DIV1;
  pTimeBaseCfg.Mode = HRTIM_MODE_CONTINUOUS;
  if (HAL_HRTIM_TimeBaseConfig(&hhrtim, HRTIM_TIMERINDEX_TIMER_A, &pTimeBaseCfg) != HAL_OK)
  {
    Error_Handler();
  }
  pTimerCfg.InterruptRequests = HRTIM_TIM_IT_NONE;
  pTimerCfg.DMARequests = HRTIM_TIM_DMA_NONE;
  pTimerCfg.DMASrcAddress = 0x0000;
  pTimerCfg.DMADstAddress = 0x0000;
  pTimerCfg.DMASize = 0x1;
  pTimerCfg.HalfModeEnable = HRTIM_HALFMODE_DISABLED;
  pTimerCfg.StartOnSync = HRTIM_SYNCSTART_DISABLED;
  pTimerCfg.ResetOnSync = HRTIM_SYNCRESET_DISABLED;
  pTimerCfg.DACSynchro = HRTIM_DACSYNC_NONE;
  pTimerCfg.PreloadEnable = HRTIM_PRELOAD_ENABLED;
  pTimerCfg.UpdateGating = HRTIM_UPDATEGATING_INDEPENDENT;
  pTimerCfg.BurstMode = HRTIM_TIMERBURSTMODE_MAINTAINCLOCK;
  pTimerCfg.RepetitionUpdate = HRTIM_UPDATEONREPETITION_DISABLED;
  pTimerCfg.PushPull = HRTIM_TIMPUSHPULLMODE_DISABLED;
  pTimerCfg.FaultEnable = HRTIM_TIMFAULTENABLE_NONE;
  pTimerCfg.FaultLock = HRTIM_TIMFAULTLOCK_READWRITE;
  pTimerCfg.DeadTimeInsertion = HRTIM_TIMDEADTIMEINSERTION_DISABLED;
  pTimerCfg.DelayedProtectionMode = HRTIM_TIMER_A_B_C_DELAYEDPROTECTION_DISABLED;
  pTimerCfg.UpdateTrigger = HRTIM_TIMUPDATETRIGGER_NONE;
  pTimerCfg.ResetTrigger = HRTIM_TIMRESETTRIGGER_EEV_1;
  pTimerCfg.ResetUpdate = HRTIM_TIMUPDATEONRESET_ENABLED;
  if (HAL_HRTIM_WaveformTimerConfig(&hhrtim, HRTIM_TIMERINDEX_TIMER_A, &pTimerCfg) != HAL_OK)
  {
    Error_Handler();
  }
  if (HAL_HRTIM_WaveformTimerConfig(&hhrtim, HRTIM_TIMERINDEX_TIMER_B, &pTimerCfg) != HAL_OK)
  {
    Error_Handler();
  }
  if (HAL_HRTIM_WaveformTimerConfig(&hhrtim, HRTIM_TIMERINDEX_TIMER_C, &pTimerCfg) != HAL_OK)
  {
    Error_Handler();
  }
  pTimerCfg.DelayedProtectionMode = HRTIM_TIMER_D_E_DELAYEDPROTECTION_DISABLED;
  if (HAL_HRTIM_WaveformTimerConfig(&hhrtim, HRTIM_TIMERINDEX_TIMER_D, &pTimerCfg) != HAL_OK)
  {
    Error_Handler();
  }
  pCompareCfg.CompareValue = 0x00005A00/2;
  if (HAL_HRTIM_WaveformCompareConfig(&hhrtim, HRTIM_TIMERINDEX_TIMER_A, HRTIM_COMPAREUNIT_1, &pCompareCfg) != HAL_OK)
  {
    Error_Handler();
  }
  pCompareCfg.AutoDelayedMode = HRTIM_AUTODELAYEDMODE_REGULAR;
  pCompareCfg.AutoDelayedTimeout = 0x0000;

  if (HAL_HRTIM_WaveformCompareConfig(&hhrtim, HRTIM_TIMERINDEX_TIMER_A, HRTIM_COMPAREUNIT_2, &pCompareCfg) != HAL_OK)
  {
    Error_Handler();
  }

  if (HAL_HRTIM_WaveformCompareConfig(&hhrtim, HRTIM_TIMERINDEX_TIMER_B, HRTIM_COMPAREUNIT_2, &pCompareCfg) != HAL_OK)
  {
    Error_Handler();
  }

  if (HAL_HRTIM_WaveformCompareConfig(&hhrtim, HRTIM_TIMERINDEX_TIMER_C, HRTIM_COMPAREUNIT_2, &pCompareCfg) != HAL_OK)
  {
    Error_Handler();
  }

  if (HAL_HRTIM_WaveformCompareConfig(&hhrtim, HRTIM_TIMERINDEX_TIMER_D, HRTIM_COMPAREUNIT_2, &pCompareCfg) != HAL_OK)
  {
    Error_Handler();
  }
  pOutputCfg.Polarity = HRTIM_OUTPUTPOLARITY_HIGH;
  pOutputCfg.SetSource = HRTIM_OUTPUTSET_EEV_1|HRTIM_OUTPUTSET_TIMPER;
  pOutputCfg.ResetSource = HRTIM_OUTPUTRESET_TIMCMP1;
  pOutputCfg.IdleMode = HRTIM_OUTPUTIDLEMODE_NONE;
  pOutputCfg.IdleLevel = HRTIM_OUTPUTIDLELEVEL_INACTIVE;
  pOutputCfg.FaultLevel = HRTIM_OUTPUTFAULTLEVEL_NONE;
  pOutputCfg.ChopperModeEnable = HRTIM_OUTPUTCHOPPERMODE_DISABLED;
  pOutputCfg.BurstModeEntryDelayed = HRTIM_OUTPUTBURSTMODEENTRY_REGULAR;
  if (HAL_HRTIM_WaveformOutputConfig(&hhrtim, HRTIM_TIMERINDEX_TIMER_A, HRTIM_OUTPUT_TA1, &pOutputCfg) != HAL_OK)
  {
    Error_Handler();
  }
  if (HAL_HRTIM_WaveformOutputConfig(&hhrtim, HRTIM_TIMERINDEX_TIMER_B, HRTIM_OUTPUT_TB1, &pOutputCfg) != HAL_OK)
  {
    Error_Handler();
  }
  if (HAL_HRTIM_WaveformOutputConfig(&hhrtim, HRTIM_TIMERINDEX_TIMER_C, HRTIM_OUTPUT_TC1, &pOutputCfg) != HAL_OK)
  {
    Error_Handler();
  }
  if (HAL_HRTIM_WaveformOutputConfig(&hhrtim, HRTIM_TIMERINDEX_TIMER_D, HRTIM_OUTPUT_TD1, &pOutputCfg) != HAL_OK)
  {
    Error_Handler();
  }
  pOutputCfg.ResetSource = HRTIM_OUTPUTRESET_TIMCMP2;
  if (HAL_HRTIM_WaveformOutputConfig(&hhrtim, HRTIM_TIMERINDEX_TIMER_A, HRTIM_OUTPUT_TA2, &pOutputCfg) != HAL_OK)
  {
    Error_Handler();
  }
  if (HAL_HRTIM_WaveformOutputConfig(&hhrtim, HRTIM_TIMERINDEX_TIMER_B, HRTIM_OUTPUT_TB2, &pOutputCfg) != HAL_OK)
  {
    Error_Handler();
  }
  if (HAL_HRTIM_WaveformOutputConfig(&hhrtim, HRTIM_TIMERINDEX_TIMER_C, HRTIM_OUTPUT_TC2, &pOutputCfg) != HAL_OK)
  {
    Error_Handler();
  }
  if (HAL_HRTIM_WaveformOutputConfig(&hhrtim, HRTIM_TIMERINDEX_TIMER_D, HRTIM_OUTPUT_TD2, &pOutputCfg) != HAL_OK)
  {
    Error_Handler();
  }
  if (HAL_HRTIM_TimeBaseConfig(&hhrtim, HRTIM_TIMERINDEX_TIMER_B, &pTimeBaseCfg) != HAL_OK)
  {
    Error_Handler();
  }
  if (HAL_HRTIM_WaveformCompareConfig(&hhrtim, HRTIM_TIMERINDEX_TIMER_B, HRTIM_COMPAREUNIT_1, &pCompareCfg) != HAL_OK)
  {
    Error_Handler();
  }
  if (HAL_HRTIM_TimeBaseConfig(&hhrtim, HRTIM_TIMERINDEX_TIMER_C, &pTimeBaseCfg) != HAL_OK)
  {
    Error_Handler();
  }
  if (HAL_HRTIM_WaveformCompareConfig(&hhrtim, HRTIM_TIMERINDEX_TIMER_C, HRTIM_COMPAREUNIT_1, &pCompareCfg) != HAL_OK)
  {
    Error_Handler();
  }
  if (HAL_HRTIM_TimeBaseConfig(&hhrtim, HRTIM_TIMERINDEX_TIMER_D, &pTimeBaseCfg) != HAL_OK)
  {
    Error_Handler();
  }
  if (HAL_HRTIM_WaveformCompareConfig(&hhrtim, HRTIM_TIMERINDEX_TIMER_D, HRTIM_COMPAREUNIT_1, &pCompareCfg) != HAL_OK)
  {
    Error_Handler();
  }
  HAL_HRTIM_MspPostInit(&hhrtim);

}

static void MX_LPTIM1_Init(void)
{

  hlptim1.Instance = LPTIM1;
  hlptim1.Init.Clock.Source = LPTIM_CLOCKSOURCE_APBCLOCK_LPOSC;
  hlptim1.Init.Clock.Prescaler = LPTIM_PRESCALER_DIV1;
  hlptim1.Init.Trigger.Source = LPTIM_TRIGSOURCE_SOFTWARE;
  hlptim1.Init.OutputPolarity = LPTIM_OUTPUTPOLARITY_LOW;
  hlptim1.Init.UpdateMode = LPTIM_UPDATE_IMMEDIATE;
  hlptim1.Init.CounterSource = LPTIM_COUNTERSOURCE_INTERNAL;
  hlptim1.Init.Input1Source = LPTIM_INPUT1SOURCE_GPIO;
  hlptim1.Init.Input2Source = LPTIM_INPUT2SOURCE_GPIO;
  if (HAL_LPTIM_Init(&hlptim1) != HAL_OK)
  {
    Error_Handler();
  }

}

static void MX_TIM1_Init(void)
{

  TIM_ClockConfigTypeDef sClockSourceConfig = {0};
  TIM_MasterConfigTypeDef sMasterConfig = {0};
  TIM_OC_InitTypeDef sConfigOC = {0};
  TIM_BreakDeadTimeConfigTypeDef sBreakDeadTimeConfig = {0};

  htim1.Instance = TIM1;
  htim1.Init.Prescaler = 0;
  htim1.Init.CounterMode = TIM_COUNTERMODE_UP;
  htim1.Init.Period = 24000-1;
  htim1.Init.ClockDivision = TIM_CLOCKDIVISION_DIV1;
  htim1.Init.RepetitionCounter = 0;
  htim1.Init.AutoReloadPreload = TIM_AUTORELOAD_PRELOAD_ENABLE;
  if (HAL_TIM_Base_Init(&htim1) != HAL_OK)
  {
    Error_Handler();
  }
  sClockSourceConfig.ClockSource = TIM_CLOCKSOURCE_INTERNAL;
  if (HAL_TIM_ConfigClockSource(&htim1, &sClockSourceConfig) != HAL_OK)
  {
    Error_Handler();
  }
  if (HAL_TIM_PWM_Init(&htim1) != HAL_OK)
  {
    Error_Handler();
  }
  sMasterConfig.MasterOutputTrigger = TIM_TRGO_UPDATE;
  sMasterConfig.MasterOutputTrigger2 = TIM_TRGO2_RESET;
  sMasterConfig.MasterSlaveMode = TIM_MASTERSLAVEMODE_DISABLE;
  if (HAL_TIMEx_MasterConfigSynchronization(&htim1, &sMasterConfig) != HAL_OK)
  {
    Error_Handler();
  }
  sConfigOC.OCMode = TIM_OCMODE_PWM1;
  sConfigOC.Pulse = 0;
  sConfigOC.OCPolarity = TIM_OCPOLARITY_HIGH;
  sConfigOC.OCNPolarity = TIM_OCNPOLARITY_HIGH;
  sConfigOC.OCFastMode = TIM_OCFAST_DISABLE;
  sConfigOC.OCIdleState = TIM_OCIDLESTATE_RESET;
  sConfigOC.OCNIdleState = TIM_OCNIDLESTATE_RESET;
  if (HAL_TIM_PWM_ConfigChannel(&htim1, &sConfigOC, TIM_CHANNEL_1) != HAL_OK)
  {
    Error_Handler();
  }
  if (HAL_TIM_PWM_ConfigChannel(&htim1, &sConfigOC, TIM_CHANNEL_2) != HAL_OK)
  {
    Error_Handler();
  }
  if (HAL_TIM_PWM_ConfigChannel(&htim1, &sConfigOC, TIM_CHANNEL_3) != HAL_OK)
  {
    Error_Handler();
  }
  if (HAL_TIM_PWM_ConfigChannel(&htim1, &sConfigOC, TIM_CHANNEL_4) != HAL_OK)
  {
    Error_Handler();
  }
  sBreakDeadTimeConfig.OffStateRunMode = TIM_OSSR_DISABLE;
  sBreakDeadTimeConfig.OffStateIDLEMode = TIM_OSSI_DISABLE;
  sBreakDeadTimeConfig.LockLevel = TIM_LOCKLEVEL_OFF;
  sBreakDeadTimeConfig.DeadTime = 0;
  sBreakDeadTimeConfig.BreakState = TIM_BREAK_DISABLE;
  sBreakDeadTimeConfig.BreakPolarity = TIM_BREAKPOLARITY_HIGH;
  sBreakDeadTimeConfig.BreakFilter = 0;
  sBreakDeadTimeConfig.Break2State = TIM_BREAK2_DISABLE;
  sBreakDeadTimeConfig.Break2Polarity = TIM_BREAK2POLARITY_HIGH;
  sBreakDeadTimeConfig.Break2Filter = 0;
  sBreakDeadTimeConfig.AutomaticOutput = TIM_AUTOMATICOUTPUT_DISABLE;
  if (HAL_TIMEx_ConfigBreakDeadTime(&htim1, &sBreakDeadTimeConfig) != HAL_OK)
  {
    Error_Handler();
  }
  HAL_TIM_MspPostInit(&htim1);

}

static void MX_TIM2_Init(void)
{

  TIM_ClockConfigTypeDef sClockSourceConfig = {0};
  TIM_MasterConfigTypeDef sMasterConfig = {0};
  TIM_OC_InitTypeDef sConfigOC = {0};

  htim2.Instance = TIM2;
  htim2.Init.Prescaler = 0;
  htim2.Init.CounterMode = TIM_COUNTERMODE_UP;
  htim2.Init.Period = 24000-1;
  htim2.Init.ClockDivision = TIM_CLOCKDIVISION_DIV1;
  htim2.Init.AutoReloadPreload = TIM_AUTORELOAD_PRELOAD_ENABLE;
  if (HAL_TIM_Base_Init(&htim2) != HAL_OK)
  {
    Error_Handler();
  }
  sClockSourceConfig.ClockSource = TIM_CLOCKSOURCE_INTERNAL;
  if (HAL_TIM_ConfigClockSource(&htim2, &sClockSourceConfig) != HAL_OK)
  {
    Error_Handler();
  }
  if (HAL_TIM_PWM_Init(&htim2) != HAL_OK)
  {
    Error_Handler();
  }
  sMasterConfig.MasterOutputTrigger = TIM_TRGO_RESET;
  sMasterConfig.MasterSlaveMode = TIM_MASTERSLAVEMODE_DISABLE;
  if (HAL_TIMEx_MasterConfigSynchronization(&htim2, &sMasterConfig) != HAL_OK)
  {
    Error_Handler();
  }
  sConfigOC.OCMode = TIM_OCMODE_PWM1;
  sConfigOC.Pulse = 0;
  sConfigOC.OCPolarity = TIM_OCPOLARITY_HIGH;
  sConfigOC.OCFastMode = TIM_OCFAST_DISABLE;
  if (HAL_TIM_PWM_ConfigChannel(&htim2, &sConfigOC, TIM_CHANNEL_1) != HAL_OK)
  {
    Error_Handler();
  }
  HAL_TIM_MspPostInit(&htim2);

}

static void MX_TIM4_Init(void)
{

  TIM_ClockConfigTypeDef sClockSourceConfig = {0};
  TIM_MasterConfigTypeDef sMasterConfig = {0};
  TIM_OC_InitTypeDef sConfigOC = {0};

  htim4.Instance = TIM4;
  htim4.Init.Prescaler = 0;
  htim4.Init.CounterMode = TIM_COUNTERMODE_UP;
  htim4.Init.Period = 24000-1;
  htim4.Init.ClockDivision = TIM_CLOCKDIVISION_DIV1;
  htim4.Init.AutoReloadPreload = TIM_AUTORELOAD_PRELOAD_ENABLE;
  if (HAL_TIM_Base_Init(&htim4) != HAL_OK)
  {
    Error_Handler();
  }
  sClockSourceConfig.ClockSource = TIM_CLOCKSOURCE_INTERNAL;
  if (HAL_TIM_ConfigClockSource(&htim4, &sClockSourceConfig) != HAL_OK)
  {
    Error_Handler();
  }
  if (HAL_TIM_PWM_Init(&htim4) != HAL_OK)
  {
    Error_Handler();
  }
  sMasterConfig.MasterOutputTrigger = TIM_TRGO_RESET;
  sMasterConfig.MasterSlaveMode = TIM_MASTERSLAVEMODE_DISABLE;
  if (HAL_TIMEx_MasterConfigSynchronization(&htim4, &sMasterConfig) != HAL_OK)
  {
    Error_Handler();
  }
  sConfigOC.OCMode = TIM_OCMODE_PWM1;
  sConfigOC.Pulse = 0;
  sConfigOC.OCPolarity = TIM_OCPOLARITY_HIGH;
  sConfigOC.OCFastMode = TIM_OCFAST_DISABLE;
  if (HAL_TIM_PWM_ConfigChannel(&htim4, &sConfigOC, TIM_CHANNEL_1) != HAL_OK)
  {
    Error_Handler();
  }
  if (HAL_TIM_PWM_ConfigChannel(&htim4, &sConfigOC, TIM_CHANNEL_2) != HAL_OK)
  {
    Error_Handler();
  }
  if (HAL_TIM_PWM_ConfigChannel(&htim4, &sConfigOC, TIM_CHANNEL_3) != HAL_OK)
  {
    Error_Handler();
  }
  if (HAL_TIM_PWM_ConfigChannel(&htim4, &sConfigOC, TIM_CHANNEL_4) != HAL_OK)
  {
    Error_Handler();
  }
  HAL_TIM_MspPostInit(&htim4);

}

static void MX_TIM5_Init(void)
{

  TIM_ClockConfigTypeDef sClockSourceConfig = {0};
  TIM_MasterConfigTypeDef sMasterConfig = {0};
  TIM_OC_InitTypeDef sConfigOC = {0};

  htim5.Instance = TIM5;
  htim5.Init.Prescaler = 0;
  htim5.Init.CounterMode = TIM_COUNTERMODE_UP;
  htim5.Init.Period = 24000-1;
  htim5.Init.ClockDivision = TIM_CLOCKDIVISION_DIV1;
  htim5.Init.AutoReloadPreload = TIM_AUTORELOAD_PRELOAD_ENABLE;
  if (HAL_TIM_Base_Init(&htim5) != HAL_OK)
  {
    Error_Handler();
  }
  sClockSourceConfig.ClockSource = TIM_CLOCKSOURCE_INTERNAL;
  if (HAL_TIM_ConfigClockSource(&htim5, &sClockSourceConfig) != HAL_OK)
  {
    Error_Handler();
  }
  if (HAL_TIM_PWM_Init(&htim5) != HAL_OK)
  {
    Error_Handler();
  }
  sMasterConfig.MasterOutputTrigger = TIM_TRGO_RESET;
  sMasterConfig.MasterSlaveMode = TIM_MASTERSLAVEMODE_DISABLE;
  if (HAL_TIMEx_MasterConfigSynchronization(&htim5, &sMasterConfig) != HAL_OK)
  {
    Error_Handler();
  }
  sConfigOC.OCMode = TIM_OCMODE_PWM1;
  sConfigOC.Pulse = 0;
  sConfigOC.OCPolarity = TIM_OCPOLARITY_HIGH;
  sConfigOC.OCFastMode = TIM_OCFAST_DISABLE;
  if (HAL_TIM_PWM_ConfigChannel(&htim5, &sConfigOC, TIM_CHANNEL_2) != HAL_OK)
  {
    Error_Handler();
  }
  if (HAL_TIM_PWM_ConfigChannel(&htim5, &sConfigOC, TIM_CHANNEL_3) != HAL_OK)
  {
    Error_Handler();
  }
  HAL_TIM_MspPostInit(&htim5);

}

static void MX_TIM8_Init(void)
{

  TIM_ClockConfigTypeDef sClockSourceConfig = {0};
  TIM_MasterConfigTypeDef sMasterConfig = {0};
  TIM_OC_InitTypeDef sConfigOC = {0};
  TIM_BreakDeadTimeConfigTypeDef sBreakDeadTimeConfig = {0};

  htim8.Instance = TIM8;
  htim8.Init.Prescaler = 0;
  htim8.Init.CounterMode = TIM_COUNTERMODE_UP;
  htim8.Init.Period = 24000-1;
  htim8.Init.ClockDivision = TIM_CLOCKDIVISION_DIV1;
  htim8.Init.RepetitionCounter = 0;
  htim8.Init.AutoReloadPreload = TIM_AUTORELOAD_PRELOAD_ENABLE;
  if (HAL_TIM_Base_Init(&htim8) != HAL_OK)
  {
    Error_Handler();
  }
  sClockSourceConfig.ClockSource = TIM_CLOCKSOURCE_INTERNAL;
  if (HAL_TIM_ConfigClockSource(&htim8, &sClockSourceConfig) != HAL_OK)
  {
    Error_Handler();
  }
  if (HAL_TIM_PWM_Init(&htim8) != HAL_OK)
  {
    Error_Handler();
  }
  sMasterConfig.MasterOutputTrigger = TIM_TRGO_RESET;
  sMasterConfig.MasterOutputTrigger2 = TIM_TRGO2_RESET;
  sMasterConfig.MasterSlaveMode = TIM_MASTERSLAVEMODE_DISABLE;
  if (HAL_TIMEx_MasterConfigSynchronization(&htim8, &sMasterConfig) != HAL_OK)
  {
    Error_Handler();
  }
  sConfigOC.OCMode = TIM_OCMODE_PWM1;
  sConfigOC.Pulse = 0;
  sConfigOC.OCPolarity = TIM_OCPOLARITY_HIGH;
  sConfigOC.OCFastMode = TIM_OCFAST_DISABLE;
  sConfigOC.OCIdleState = TIM_OCIDLESTATE_RESET;
  sConfigOC.OCNIdleState = TIM_OCNIDLESTATE_RESET;
  if (HAL_TIM_PWM_ConfigChannel(&htim8, &sConfigOC, TIM_CHANNEL_4) != HAL_OK)
  {
    Error_Handler();
  }
  sBreakDeadTimeConfig.OffStateRunMode = TIM_OSSR_DISABLE;
  sBreakDeadTimeConfig.OffStateIDLEMode = TIM_OSSI_DISABLE;
  sBreakDeadTimeConfig.LockLevel = TIM_LOCKLEVEL_OFF;
  sBreakDeadTimeConfig.DeadTime = 0;
  sBreakDeadTimeConfig.BreakState = TIM_BREAK_DISABLE;
  sBreakDeadTimeConfig.BreakPolarity = TIM_BREAKPOLARITY_HIGH;
  sBreakDeadTimeConfig.BreakFilter = 0;
  sBreakDeadTimeConfig.Break2State = TIM_BREAK2_DISABLE;
  sBreakDeadTimeConfig.Break2Polarity = TIM_BREAK2POLARITY_HIGH;
  sBreakDeadTimeConfig.Break2Filter = 0;
  sBreakDeadTimeConfig.AutomaticOutput = TIM_AUTOMATICOUTPUT_DISABLE;
  if (HAL_TIMEx_ConfigBreakDeadTime(&htim8, &sBreakDeadTimeConfig) != HAL_OK)
  {
    Error_Handler();
  }
  HAL_TIM_MspPostInit(&htim8);

}

static void MX_TIM12_Init(void)
{

  TIM_ClockConfigTypeDef sClockSourceConfig = {0};
  TIM_MasterConfigTypeDef sMasterConfig = {0};
  TIM_OC_InitTypeDef sConfigOC = {0};

  htim12.Instance = TIM12;
  htim12.Init.Prescaler = 0;
  htim12.Init.CounterMode = TIM_COUNTERMODE_UP;
  htim12.Init.Period = 24000-1;
  htim12.Init.ClockDivision = TIM_CLOCKDIVISION_DIV1;
  htim12.Init.AutoReloadPreload = TIM_AUTORELOAD_PRELOAD_ENABLE;
  if (HAL_TIM_Base_Init(&htim12) != HAL_OK)
  {
    Error_Handler();
  }
  sClockSourceConfig.ClockSource = TIM_CLOCKSOURCE_INTERNAL;
  if (HAL_TIM_ConfigClockSource(&htim12, &sClockSourceConfig) != HAL_OK)
  {
    Error_Handler();
  }
  if (HAL_TIM_PWM_Init(&htim12) != HAL_OK)
  {
    Error_Handler();
  }
  sMasterConfig.MasterOutputTrigger = TIM_TRGO_RESET;
  sMasterConfig.MasterSlaveMode = TIM_MASTERSLAVEMODE_DISABLE;
  if (HAL_TIMEx_MasterConfigSynchronization(&htim12, &sMasterConfig) != HAL_OK)
  {
    Error_Handler();
  }
  sConfigOC.OCMode = TIM_OCMODE_PWM1;
  sConfigOC.Pulse = 0;
  sConfigOC.OCPolarity = TIM_OCPOLARITY_HIGH;
  sConfigOC.OCFastMode = TIM_OCFAST_DISABLE;
  if (HAL_TIM_PWM_ConfigChannel(&htim12, &sConfigOC, TIM_CHANNEL_2) != HAL_OK)
  {
    Error_Handler();
  }
  HAL_TIM_MspPostInit(&htim12);

}

static void MX_TIM13_Init(void)
{

  TIM_OC_InitTypeDef sConfigOC = {0};

  htim13.Instance = TIM13;
  htim13.Init.Prescaler = 0;
  htim13.Init.CounterMode = TIM_COUNTERMODE_UP;
  htim13.Init.Period = 24000-1;
  htim13.Init.ClockDivision = TIM_CLOCKDIVISION_DIV1;
  htim13.Init.AutoReloadPreload = TIM_AUTORELOAD_PRELOAD_ENABLE;
  if (HAL_TIM_Base_Init(&htim13) != HAL_OK)
  {
    Error_Handler();
  }
  if (HAL_TIM_PWM_Init(&htim13) != HAL_OK)
  {
    Error_Handler();
  }
  sConfigOC.OCMode = TIM_OCMODE_PWM1;
  sConfigOC.Pulse = 0;
  sConfigOC.OCPolarity = TIM_OCPOLARITY_HIGH;
  sConfigOC.OCFastMode = TIM_OCFAST_DISABLE;
  if (HAL_TIM_PWM_ConfigChannel(&htim13, &sConfigOC, TIM_CHANNEL_1) != HAL_OK)
  {
    Error_Handler();
  }
  HAL_TIM_MspPostInit(&htim13);

}

static void MX_TIM14_Init(void)
{

  TIM_OC_InitTypeDef sConfigOC = {0};

  htim14.Instance = TIM14;
  htim14.Init.Prescaler = 0;
  htim14.Init.CounterMode = TIM_COUNTERMODE_UP;
  htim14.Init.Period = 24000-1;
  htim14.Init.ClockDivision = TIM_CLOCKDIVISION_DIV1;
  htim14.Init.AutoReloadPreload = TIM_AUTORELOAD_PRELOAD_ENABLE;
  if (HAL_TIM_Base_Init(&htim14) != HAL_OK)
  {
    Error_Handler();
  }
  if (HAL_TIM_PWM_Init(&htim14) != HAL_OK)
  {
    Error_Handler();
  }
  sConfigOC.OCMode = TIM_OCMODE_PWM1;
  sConfigOC.Pulse = 0;
  sConfigOC.OCPolarity = TIM_OCPOLARITY_HIGH;
  sConfigOC.OCFastMode = TIM_OCFAST_DISABLE;
  if (HAL_TIM_PWM_ConfigChannel(&htim14, &sConfigOC, TIM_CHANNEL_1) != HAL_OK)
  {
    Error_Handler();
  }
  HAL_TIM_MspPostInit(&htim14);

}

static void MX_TIM15_Init(void)
{

  TIM_ClockConfigTypeDef sClockSourceConfig = {0};
  TIM_MasterConfigTypeDef sMasterConfig = {0};
  TIM_OC_InitTypeDef sConfigOC = {0};
  TIM_BreakDeadTimeConfigTypeDef sBreakDeadTimeConfig = {0};

  htim15.Instance = TIM15;
  htim15.Init.Prescaler = 0;
  htim15.Init.CounterMode = TIM_COUNTERMODE_UP;
  htim15.Init.Period = 24000-1;
  htim15.Init.ClockDivision = TIM_CLOCKDIVISION_DIV1;
  htim15.Init.RepetitionCounter = 0;
  htim15.Init.AutoReloadPreload = TIM_AUTORELOAD_PRELOAD_ENABLE;
  if (HAL_TIM_Base_Init(&htim15) != HAL_OK)
  {
    Error_Handler();
  }
  sClockSourceConfig.ClockSource = TIM_CLOCKSOURCE_INTERNAL;
  if (HAL_TIM_ConfigClockSource(&htim15, &sClockSourceConfig) != HAL_OK)
  {
    Error_Handler();
  }
  if (HAL_TIM_PWM_Init(&htim15) != HAL_OK)
  {
    Error_Handler();
  }
  sMasterConfig.MasterOutputTrigger = TIM_TRGO_RESET;
  sMasterConfig.MasterSlaveMode = TIM_MASTERSLAVEMODE_DISABLE;
  if (HAL_TIMEx_MasterConfigSynchronization(&htim15, &sMasterConfig) != HAL_OK)
  {
    Error_Handler();
  }
  sConfigOC.OCMode = TIM_OCMODE_PWM1;
  sConfigOC.Pulse = 0;
  sConfigOC.OCPolarity = TIM_OCPOLARITY_HIGH;
  sConfigOC.OCNPolarity = TIM_OCNPOLARITY_HIGH;
  sConfigOC.OCFastMode = TIM_OCFAST_DISABLE;
  sConfigOC.OCIdleState = TIM_OCIDLESTATE_RESET;
  sConfigOC.OCNIdleState = TIM_OCNIDLESTATE_RESET;
  if (HAL_TIM_PWM_ConfigChannel(&htim15, &sConfigOC, TIM_CHANNEL_1) != HAL_OK)
  {
    Error_Handler();
  }
  if (HAL_TIM_PWM_ConfigChannel(&htim15, &sConfigOC, TIM_CHANNEL_2) != HAL_OK)
  {
    Error_Handler();
  }
  sBreakDeadTimeConfig.OffStateRunMode = TIM_OSSR_DISABLE;
  sBreakDeadTimeConfig.OffStateIDLEMode = TIM_OSSI_DISABLE;
  sBreakDeadTimeConfig.LockLevel = TIM_LOCKLEVEL_OFF;
  sBreakDeadTimeConfig.DeadTime = 0;
  sBreakDeadTimeConfig.BreakState = TIM_BREAK_DISABLE;
  sBreakDeadTimeConfig.BreakPolarity = TIM_BREAKPOLARITY_HIGH;
  sBreakDeadTimeConfig.BreakFilter = 0;
  sBreakDeadTimeConfig.AutomaticOutput = TIM_AUTOMATICOUTPUT_DISABLE;
  if (HAL_TIMEx_ConfigBreakDeadTime(&htim15, &sBreakDeadTimeConfig) != HAL_OK)
  {
    Error_Handler();
  }
  HAL_TIM_MspPostInit(&htim15);

}

static void MX_TIM16_Init(void)
{

  TIM_OC_InitTypeDef sConfigOC = {0};
  TIM_BreakDeadTimeConfigTypeDef sBreakDeadTimeConfig = {0};

  htim16.Instance = TIM16;
  htim16.Init.Prescaler = 0;
  htim16.Init.CounterMode = TIM_COUNTERMODE_UP;
  htim16.Init.Period = 24000-1;
  htim16.Init.ClockDivision = TIM_CLOCKDIVISION_DIV1;
  htim16.Init.RepetitionCounter = 0;
  htim16.Init.AutoReloadPreload = TIM_AUTORELOAD_PRELOAD_ENABLE;
  if (HAL_TIM_Base_Init(&htim16) != HAL_OK)
  {
    Error_Handler();
  }
  if (HAL_TIM_PWM_Init(&htim16) != HAL_OK)
  {
    Error_Handler();
  }
  sConfigOC.OCMode = TIM_OCMODE_PWM1;
  sConfigOC.Pulse = 0;
  sConfigOC.OCPolarity = TIM_OCPOLARITY_HIGH;
  sConfigOC.OCNPolarity = TIM_OCNPOLARITY_HIGH;
  sConfigOC.OCFastMode = TIM_OCFAST_DISABLE;
  sConfigOC.OCIdleState = TIM_OCIDLESTATE_RESET;
  sConfigOC.OCNIdleState = TIM_OCNIDLESTATE_RESET;
  if (HAL_TIM_PWM_ConfigChannel(&htim16, &sConfigOC, TIM_CHANNEL_1) != HAL_OK)
  {
    Error_Handler();
  }
  sBreakDeadTimeConfig.OffStateRunMode = TIM_OSSR_DISABLE;
  sBreakDeadTimeConfig.OffStateIDLEMode = TIM_OSSI_DISABLE;
  sBreakDeadTimeConfig.LockLevel = TIM_LOCKLEVEL_OFF;
  sBreakDeadTimeConfig.DeadTime = 0;
  sBreakDeadTimeConfig.BreakState = TIM_BREAK_DISABLE;
  sBreakDeadTimeConfig.BreakPolarity = TIM_BREAKPOLARITY_HIGH;
  sBreakDeadTimeConfig.BreakFilter = 0;
  sBreakDeadTimeConfig.AutomaticOutput = TIM_AUTOMATICOUTPUT_DISABLE;
  if (HAL_TIMEx_ConfigBreakDeadTime(&htim16, &sBreakDeadTimeConfig) != HAL_OK)
  {
    Error_Handler();
  }
  HAL_TIM_MspPostInit(&htim16);

}

static void MX_UART4_Init(void)
{

  LL_USART_InitTypeDef UART_InitStruct = {0};

  LL_GPIO_InitTypeDef GPIO_InitStruct = {0};
  RCC_PeriphCLKInitTypeDef PeriphClkInitStruct = {0};

  /** Initializes the peripherals clock
  */
  PeriphClkInitStruct.PeriphClockSelection = RCC_PERIPHCLK_UART4;
  PeriphClkInitStruct.Usart234578ClockSelection = RCC_USART234578CLKSOURCE_D2PCLK1;
  if (HAL_RCCEx_PeriphCLKConfig(&PeriphClkInitStruct) != HAL_OK)
  {
    Error_Handler();
  }

  /* Peripheral clock enable */
  LL_APB1_GRP1_EnableClock(LL_APB1_GRP1_PERIPH_UART4);

  LL_AHB4_GRP1_EnableClock(LL_AHB4_GRP1_PERIPH_GPIOC);
  /**UART4 GPIO Configuration
  PC10   ------> UART4_TX
  PC11   ------> UART4_RX
  */
  GPIO_InitStruct.Pin = LL_GPIO_PIN_10|LL_GPIO_PIN_11;
  GPIO_InitStruct.Mode = LL_GPIO_MODE_ALTERNATE;
  GPIO_InitStruct.Speed = LL_GPIO_SPEED_FREQ_LOW;
  GPIO_InitStruct.OutputType = LL_GPIO_OUTPUT_PUSHPULL;
  GPIO_InitStruct.Pull = LL_GPIO_PULL_NO;
  GPIO_InitStruct.Alternate = LL_GPIO_AF_8;
  LL_GPIO_Init(GPIOC, &GPIO_InitStruct);

  /* UART4 interrupt Init */
  NVIC_SetPriority(UART4_IRQn, NVIC_EncodePriority(NVIC_GetPriorityGrouping(),0, 0));
  NVIC_EnableIRQ(UART4_IRQn);

  UART_InitStruct.PrescalerValue = LL_USART_PRESCALER_DIV1;
  UART_InitStruct.BaudRate = 115200;
  UART_InitStruct.DataWidth = LL_USART_DATAWIDTH_8B;
  UART_InitStruct.StopBits = LL_USART_STOPBITS_1;
  UART_InitStruct.Parity = LL_USART_PARITY_NONE;
  UART_InitStruct.TransferDirection = LL_USART_DIRECTION_TX_RX;
  UART_InitStruct.HardwareFlowControl = LL_USART_HWCONTROL_NONE;
  UART_InitStruct.OverSampling = LL_USART_OVERSAMPLING_16;
  LL_USART_Init(UART4, &UART_InitStruct);
  LL_USART_DisableFIFO(UART4);
  LL_USART_SetTXFIFOThreshold(UART4, LL_USART_FIFOTHRESHOLD_1_8);
  LL_USART_SetRXFIFOThreshold(UART4, LL_USART_FIFOTHRESHOLD_1_8);
  LL_USART_ConfigAsyncMode(UART4);

  LL_USART_Enable(UART4);

  /* Polling UART4 initialisation */
  while((!(LL_USART_IsActiveFlag_TEACK(UART4))) || (!(LL_USART_IsActiveFlag_REACK(UART4))))
  {
  }
  /* USER CODE BEGIN UART4_Init 2 */
  UART4->CR1 |= (USART_CR1_TE|USART_CR1_RXNEIE|USART_CR1_RE|USART_CR1_UE);
  /* USER CODE END UART4_Init 2 */

}

static void MX_GPIO_Init(void)
{
  GPIO_InitTypeDef GPIO_InitStruct = {0};

  /* GPIO Ports Clock Enable */
  __HAL_RCC_GPIOE_CLK_ENABLE();
  __HAL_RCC_GPIOC_CLK_ENABLE();
  __HAL_RCC_GPIOH_CLK_ENABLE();
  __HAL_RCC_GPIOA_CLK_ENABLE();
  __HAL_RCC_GPIOB_CLK_ENABLE();
  __HAL_RCC_GPIOD_CLK_ENABLE();

  /*Configure GPIO pin Output Level */
  HAL_GPIO_WritePin(GPIOE, TIM1_CH3_PH_Pin|TIM1_CH4_PH_Pin|TIM2_CH1_PH_Pin|TIM8_CH4_PH_Pin
                          |TIM12_CH2_PH_Pin|TIM13_CH1_PH_Pin|TIM14_CH1_PH_Pin|TIM15_CH1_PH_Pin
                          |TIM1_CH1_PH_Pin|TIM1_CH2_PH_Pin, GPIO_PIN_RESET);

  /*Configure GPIO pin Output Level */
  HAL_GPIO_WritePin(GPIOC, TIM4_CH4_PH_Pin|TIM5_CH2_PH_Pin|TIM5_CH3_PH_Pin|TIM4_CH3_PH_Pin, GPIO_PIN_RESET);

  /*Configure GPIO pin Output Level */
  HAL_GPIO_WritePin(GPIOB, TIM4_CH1_PH_Pin|TIM4_CH2_PH_Pin, GPIO_PIN_RESET);

  /*Configure GPIO pin Output Level */
  HAL_GPIO_WritePin(GPIOD, HRTIM_CHC1_PH_Pin|HRTIM_CHC2_PH_Pin|HRTIM_CHD1_PH_Pin|HRTIM_CHD2_PH_Pin
                          |TIM15_CH2_PH_Pin|TIM16_CH1_PH_Pin|LPTIM1_OUT_PH_Pin|HRTIM_CHA1_PH_Pin
                          |HRTIM_CHA2_PH_Pin|HRTIM_CHB1_PH_Pin|HRTIM_CHB2_PH_Pin, GPIO_PIN_RESET);

  /*Configure GPIO pins : TIM1_CH3_PH_Pin TIM1_CH4_PH_Pin TIM2_CH1_PH_Pin TIM8_CH4_PH_Pin
                           TIM12_CH2_PH_Pin TIM13_CH1_PH_Pin TIM14_CH1_PH_Pin TIM15_CH1_PH_Pin
                           TIM1_CH1_PH_Pin TIM1_CH2_PH_Pin */
  GPIO_InitStruct.Pin = TIM1_CH3_PH_Pin|TIM1_CH4_PH_Pin|TIM2_CH1_PH_Pin|TIM8_CH4_PH_Pin
                          |TIM12_CH2_PH_Pin|TIM13_CH1_PH_Pin|TIM14_CH1_PH_Pin|TIM15_CH1_PH_Pin
                          |TIM1_CH1_PH_Pin|TIM1_CH2_PH_Pin;
  GPIO_InitStruct.Mode = GPIO_MODE_OUTPUT_PP;
  GPIO_InitStruct.Pull = GPIO_NOPULL;
  GPIO_InitStruct.Speed = GPIO_SPEED_FREQ_LOW;
  HAL_GPIO_Init(GPIOE, &GPIO_InitStruct);

  /*Configure GPIO pins : TIM4_CH4_PH_Pin TIM5_CH2_PH_Pin TIM5_CH3_PH_Pin TIM4_CH3_PH_Pin */
  GPIO_InitStruct.Pin = TIM4_CH4_PH_Pin|TIM5_CH2_PH_Pin|TIM5_CH3_PH_Pin|TIM4_CH3_PH_Pin;
  GPIO_InitStruct.Mode = GPIO_MODE_OUTPUT_PP;
  GPIO_InitStruct.Pull = GPIO_NOPULL;
  GPIO_InitStruct.Speed = GPIO_SPEED_FREQ_LOW;
  HAL_GPIO_Init(GPIOC, &GPIO_InitStruct);

  /*Configure GPIO pins : TIM4_CH1_PH_Pin TIM4_CH2_PH_Pin */
  GPIO_InitStruct.Pin = TIM4_CH1_PH_Pin|TIM4_CH2_PH_Pin;
  GPIO_InitStruct.Mode = GPIO_MODE_OUTPUT_PP;
  GPIO_InitStruct.Pull = GPIO_NOPULL;
  GPIO_InitStruct.Speed = GPIO_SPEED_FREQ_LOW;
  HAL_GPIO_Init(GPIOB, &GPIO_InitStruct);

  /*Configure GPIO pins : HRTIM_CHC1_PH_Pin HRTIM_CHC2_PH_Pin HRTIM_CHD1_PH_Pin HRTIM_CHD2_PH_Pin
                           TIM15_CH2_PH_Pin TIM16_CH1_PH_Pin LPTIM1_OUT_PH_Pin HRTIM_CHA1_PH_Pin
                           HRTIM_CHA2_PH_Pin HRTIM_CHB1_PH_Pin HRTIM_CHB2_PH_Pin */
  GPIO_InitStruct.Pin = HRTIM_CHC1_PH_Pin|HRTIM_CHC2_PH_Pin|HRTIM_CHD1_PH_Pin|HRTIM_CHD2_PH_Pin
                          |TIM15_CH2_PH_Pin|TIM16_CH1_PH_Pin|LPTIM1_OUT_PH_Pin|HRTIM_CHA1_PH_Pin
                          |HRTIM_CHA2_PH_Pin|HRTIM_CHB1_PH_Pin|HRTIM_CHB2_PH_Pin;
  GPIO_InitStruct.Mode = GPIO_MODE_OUTPUT_PP;
  GPIO_InitStruct.Pull = GPIO_NOPULL;
  GPIO_InitStruct.Speed = GPIO_SPEED_FREQ_LOW;
  HAL_GPIO_Init(GPIOD, &GPIO_InitStruct);

}

/* USER CODE BEGIN 4 */
void HAL_TIM_PeriodElapsedCallback(TIM_HandleTypeDef *htim)
{
	static int i = 0;  // index for actuator update
	static int t = 0; // variable to track time
	const int period = 10; // number of timer rollovers between updates
	const double step = 0.3;// max step size in volts

	/*//Used to account for period in time clicks for UART Output
		sys_timer+= 24000;
		period_ticks ++;
	*/

    if (htim==&htim1){
    	t+=1;
    	if(t%period == 0)
    	{
    		if(i>=SIN_PERIOD) i = 0;
    		//update the output
    		ref = sine_vals[i]*step;
			// inform main that the actuators need an update
    		i+=1;
			ctrl_tmr_expired = TRUE;
    	}
	}

}

/*Writes commands into the circular buffer as they are sent,
once the elements is equal to the command length, a flag is sent*/
void UART_update(){

	// echo back out the serial port
//	LL_USART_TransmitData8(UART4, recvd_byte);
	// update state machine with the character
	run_state_machine(recvd_byte);
	// Clear the flag
	data_ready = FALSE;
	// restart the uart interrupt
//	HAL_UART_Receive_IT(UART4, rx_buff, sizeof(rx_buff));
}

/*Function that is called once the number of elements in the buffer
is equal to the command length. Fills elements into an array to print */
void command_update(){

	for(index = 0; index <= CMD_LENGTH ; index ++){
		 cmd_bytes[index] = read_from_buffer(rxp);
	 }

	for(index = 0; index <= NUM_ACTUATORS ; index ++){
		cmd_ref[index] = (cmd_bytes[(2*index)+1]<<8|cmd_bytes[2*index]);
	}

//	HAL_UART_Transmit(&huart4, cmd_bytes, sizeof(cmd_bytes), 10);

	cmd_ready = FALSE;
}

static void run_state_machine(uint8_t byte)
{
	static int current_state = startByte1;
	static int counter = 0;
	int next_state;

	switch(current_state){
		case startByte1:
			if(byte == start_bytes[0]){
				next_state = startByte2;
			} else{
				next_state = current_state;
			}
			break;
		case(startByte2):
			if(byte == start_bytes[1]){
				next_state = storeMessage;
				counter = 0;
			} else{
				next_state = startByte1;
			}
			break;
		case(storeMessage):
			if(counter == CMD_LENGTH-1){
				next_state = endByte1;
			}else{
				next_state = storeMessage;
			}
			write_buffer(rxp, byte);
			counter++;
			break;
		case(endByte1):
			if(byte == end_bytes[0]){
				next_state = endByte2;
			}else{
				next_state = startByte1;
			}
			break;
		case(endByte2):
			if(byte == end_bytes[1]){
				cmd_ready = TRUE;
				LL_USART_TransmitData8(UART4,1); // test when commands are actually interpreted correctly
			}else{
			rxp->read_index = 0;
			rxp->write_index = 0;
			}
			next_state = startByte1;
			break;
		default:
			break;
	}
	current_state = next_state;
}

//void HAL_UART_RxCpltCallback(UART_HandleTypeDef*huart)
//{
//	uint8_t test_char[1];
//	test_char[0] = 0xff;
//	HAL_UART_Transmit(&huart4, test_char, sizeof(test_char), 1);
//	data_ready = TRUE;
//}

//
//void HAL_UART_TxCpltCallback(UART_HandleTypeDef*huart)
//{
// __NOP();
//}

unsigned char get_char(void) {
    unsigned char c;
    if (is_buffer_empty(rxp) == FALSE) {
        reading_rx_buffer = TRUE; /*set buffer access flag*/
        c = read_from_buffer(rxp);
        reading_rx_buffer = FALSE;
        return c;
    }
    return 0; /*no data available*/
}

static void init_buffer(struct circular_buffer *buf) {
    int i;
    buf->read_index = 0; /*initialize read index to 0 */
    buf->write_index = 0; /*initialize write index to 0 */
    buf->size = BUFFER_LENGTH; /*Set size to buffer length const*/
    for (i = 0; i < BUFFER_LENGTH; i++) { /*initialize data to zero*/
        buf->data[i] = 0;
    } /*end for */
}

/* function int is_buffer_empty(struct circular_buffer *buf)
 * takes a pointer to a circular buffer and compares the read and write indices
 * if they are equal then the buffer is empty
 */
static int8_t is_buffer_empty(struct circular_buffer *buf) {
    if (buf->read_index == buf->write_index) { //if read = write then the buffer is empty
        return TRUE;
    }
    return FALSE;
}

/*  bufFull(struct oBuffer *buf)
 * takes a pointer to a circular buffer and compares the read and write indices
 * if write+1 = read, then the buffer is full.
 */
static int8_t is_buffer_full(struct circular_buffer *buf) {
    /* write index +1 == read index is full,  the mod provides wrap around*/
    if ((buf->write_index + 1) % BUFFER_LENGTH == buf->read_index) {
        return TRUE;
    }
    return FALSE;
}

/* writeBuffer( (struct oBuffer *buf, unsigned char c)
 * takes a pointer to a circular buffer and a char to be written
 * returns SUCCESS or ERROR
 */
static int8_t write_buffer(struct circular_buffer *buf, unsigned char c) {
    if (is_buffer_full(buf) == FALSE) {
        buf->data[buf->write_index] = c;
        /*increment the write index and wrap using modulus arithmetic */
        buf->write_index = (buf->write_index + 1) % BUFFER_LENGTH;
        return SUCCESS;
    }
    return ERROR; /*no data written*/
}

/*int readBuffer(struct oBuffer *buf)
 * takes a pointer to a circular buffer
 * returns the value from the buffer
 * the read index is incremented and wrapped using modulus arithmetic
 * Returns 0 if the buffer is empty or the pointer is invalid
 */
static unsigned char read_from_buffer(struct circular_buffer *buf) {
    unsigned char val;
    if (is_buffer_empty(buf) == FALSE) {
        val = buf->data[buf->read_index]; //get the char from the buffer
        /*increment the read index and wrap using modulus arithmetic*/
        buf->read_index = (buf->read_index + 1) % BUFFER_LENGTH;
        return val;
    }
    return 0;
}

static int get_num_elements(struct circular_buffer *buf) {
    if (buf != NULL) {
        if (buf->write_index < buf->read_index) { /*test for wrap around*/
            return (buf->write_index + BUFFER_LENGTH - buf->read_index);
        } else {
            return (buf->write_index - buf->read_index);
        }
    }
    return 0;
}

static void control_update(double ref)
{
	// sign bit of the command fed to phase input on the h-bridge
	static int phase=GPIO_PIN_SET;
	static uint16_t dutycycle=0;
	double absref = 0;

	//Timer 1 channels
	// set the sign of the move (phase)
	if(cmd_ref[T1C1] < 0){
		phase = GPIO_PIN_RESET; // reverse direction
	} else {
		phase = GPIO_PIN_SET; //forward direction
	}
	HAL_GPIO_WritePin(TIM1_CH1_PH_GPIO_Port, TIM1_CH1_PH_Pin, phase);  //Starts the phase generation on each of the pins (Channels)

	// set the sign of the move (phase)
	if(cmd_ref[T1C2] < 0){
		phase = GPIO_PIN_RESET; // reverse direction
	} else {
		phase = GPIO_PIN_SET; //forward direction
	}
	HAL_GPIO_WritePin(TIM1_CH2_PH_GPIO_Port, TIM1_CH2_PH_Pin, phase);

	// set the sign of the move (phase)
	if(cmd_ref[T1C3] < 0){
		phase = GPIO_PIN_RESET; // reverse direction
	} else {
		phase = GPIO_PIN_SET; //forward direction
	}
	HAL_GPIO_WritePin(TIM1_CH3_PH_GPIO_Port, TIM1_CH3_PH_Pin, phase);

	// set the sign of the move (phase)
	if(cmd_ref[T1C4] < 0){
		phase = GPIO_PIN_RESET; // reverse direction
	} else {
		phase = GPIO_PIN_SET; //forward direction
	}
	HAL_GPIO_WritePin(TIM1_CH4_PH_GPIO_Port, TIM1_CH4_PH_Pin, phase);
	//End Timer 1

	//Timer 2 channel
		// set the sign of the move (phase)
	if(cmd_ref[T2C1] < 0){
		phase = GPIO_PIN_RESET; // reverse direction
	} else {
		phase = GPIO_PIN_SET; //forward direction
	}
	HAL_GPIO_WritePin(TIM2_CH1_PH_GPIO_Port, TIM2_CH1_PH_Pin, phase);
	//End Timer 2

	//Timer 4 channels
	// set the sign of the move (phase)
	if(cmd_ref[T4C1] < 0){
		phase = GPIO_PIN_RESET; // reverse direction
	} else {
		phase = GPIO_PIN_SET; //forward direction
	}
	HAL_GPIO_WritePin(TIM4_CH1_PH_GPIO_Port, TIM4_CH1_PH_Pin, phase);

	// set the sign of the move (phase)
	if(cmd_ref[T4C2] < 0){
		phase = GPIO_PIN_RESET; // reverse direction
	} else {
		phase = GPIO_PIN_SET; //forward direction
	}
	HAL_GPIO_WritePin(TIM4_CH2_PH_GPIO_Port, TIM4_CH2_PH_Pin, phase);

	// set the sign of the move (phase)
	if(cmd_ref[T4C3] < 0){
		phase = GPIO_PIN_RESET; // reverse direction
	} else {
		phase = GPIO_PIN_SET; //forward direction
	}
	HAL_GPIO_WritePin(TIM4_CH3_PH_GPIO_Port, TIM4_CH3_PH_Pin, phase);

	// set the sign of the move (phase)
	if(cmd_ref[T4C4] < 0){
		phase = GPIO_PIN_RESET; // reverse direction
	} else {
		phase = GPIO_PIN_SET; //forward direction
	}
	HAL_GPIO_WritePin(TIM4_CH4_PH_GPIO_Port, TIM4_CH4_PH_Pin, phase);
	//End Timer 4

	//Timer 5
	// set the sign of the move (phase)
	if(cmd_ref[T5C2] < 0){
		phase = GPIO_PIN_RESET; // reverse direction
	} else {
		phase = GPIO_PIN_SET; //forward direction
	}
	HAL_GPIO_WritePin(TIM5_CH2_PH_GPIO_Port, TIM5_CH2_PH_Pin, phase);

	// set the sign of the move (phase)
	if(cmd_ref[T5C3] < 0){
		phase = GPIO_PIN_RESET; // reverse direction
	} else {
		phase = GPIO_PIN_SET; //forward direction
	}
	HAL_GPIO_WritePin(TIM5_CH3_PH_GPIO_Port, TIM5_CH3_PH_Pin, phase);
    //End Timer 5

    //Timer 8
		// set the sign of the move (phase)
	if(cmd_ref[T8C4] < 0){
		phase = GPIO_PIN_RESET; // reverse direction
	} else {
		phase = GPIO_PIN_SET; //forward direction
	}
	HAL_GPIO_WritePin(TIM8_CH4_PH_GPIO_Port, TIM8_CH4_PH_Pin, phase);
	//End Timer 8

    //Timer 12
	// set the sign of the move (phase)
	if(cmd_ref[T12C2] < 0){
		phase = GPIO_PIN_RESET; // reverse direction
	} else {
		phase = GPIO_PIN_SET; //forward direction
	}
	HAL_GPIO_WritePin(TIM12_CH2_PH_GPIO_Port, TIM12_CH2_PH_Pin, phase);
    //End Timer 12

    //Timer 13
	// set the sign of the move (phase)
	if(cmd_ref[T13C1] < 0){
		phase = GPIO_PIN_RESET; // reverse direction
	} else {
		phase = GPIO_PIN_SET; //forward direction
	}
	HAL_GPIO_WritePin(TIM13_CH1_PH_GPIO_Port, TIM13_CH1_PH_Pin, phase);
    //End Timer 13

    //Timer 14
	// set the sign of the move (phase)
	if(cmd_ref[T14C1] < 0){
		phase = GPIO_PIN_RESET; // reverse direction
	} else {
		phase = GPIO_PIN_SET; //forward direction
	}
	HAL_GPIO_WritePin(TIM14_CH1_PH_GPIO_Port, TIM14_CH1_PH_Pin, phase);
    //End Timer 14

    //Timer 15
		// set the sign of the move (phase)
	if(cmd_ref[T15C1] < 0){
		phase = GPIO_PIN_RESET; // reverse direction
	} else {
		phase = GPIO_PIN_SET; //forward direction
	}
	HAL_GPIO_WritePin(TIM15_CH1_PH_GPIO_Port, TIM15_CH1_PH_Pin, phase);

	// set the sign of the move (phase)
	if(cmd_ref[T15C2] < 0){
		phase = GPIO_PIN_RESET; // reverse direction
	} else {
		phase = GPIO_PIN_SET; //forward direction
	}
	HAL_GPIO_WritePin(TIM15_CH2_PH_GPIO_Port, TIM15_CH2_PH_Pin, phase);
   //End Timer 15

   //Timer 16
		// set the sign of the move (phase)
	if(cmd_ref[T16C1] < 0){
		phase = GPIO_PIN_RESET; // reverse direction
	} else {
		phase = GPIO_PIN_SET; //forward direction
	}
	HAL_GPIO_WritePin(TIM16_CH1_PH_GPIO_Port, TIM16_CH1_PH_Pin, phase);
    //End Timer 16

    //HRTIM CODE HERE **************
    //High Resolution Timer CHA
	// set the sign of the move (phase)
	if(cmd_ref[HRA1] < 0){
		phase = GPIO_PIN_RESET; // reverse direction
	} else {
		phase = GPIO_PIN_SET; //forward direction
	}
	HAL_GPIO_WritePin(HRTIM_CHA1_PH_GPIO_Port, HRTIM_CHA1_PH_Pin, phase);

	// set the sign of the move (phase)
	if(cmd_ref[HRA2] < 0){
		phase = GPIO_PIN_RESET; // reverse direction
	} else {
		phase = GPIO_PIN_SET; //forward direction
	}
	HAL_GPIO_WritePin(HRTIM_CHA2_PH_GPIO_Port, HRTIM_CHA2_PH_Pin, phase);
    //End High HRTIM CHA

    //High Resolution Timer CHB
		// set the sign of the move (phase)
	if(cmd_ref[HRB1] < 0){
		phase = GPIO_PIN_RESET; // reverse direction
	} else {
		phase = GPIO_PIN_SET; //forward direction
	}
	HAL_GPIO_WritePin(HRTIM_CHB1_PH_GPIO_Port, HRTIM_CHB1_PH_Pin, phase);

	// set the sign of the move (phase)
	if(cmd_ref[HRB2] < 0){
		phase = GPIO_PIN_RESET; // reverse direction
	} else {
		phase = GPIO_PIN_SET; //forward direction
	}
	HAL_GPIO_WritePin(HRTIM_CHB2_PH_GPIO_Port, HRTIM_CHB2_PH_Pin, phase);
    //End High HRTIM CHB

    //High Resolution Timer CHC
		// set the sign of the move (phase)
	if(cmd_ref[HRC1] < 0){
		phase = GPIO_PIN_RESET; // reverse direction
	} else {
		phase = GPIO_PIN_SET; //forward direction
	}
	HAL_GPIO_WritePin(HRTIM_CHC1_PH_GPIO_Port, HRTIM_CHC1_PH_Pin, phase);

	// set the sign of the move (phase)
	if(cmd_ref[HRC2] < 0){
		phase = GPIO_PIN_RESET; // reverse direction
	} else {
		phase = GPIO_PIN_SET; //forward direction
	}
	HAL_GPIO_WritePin(HRTIM_CHC2_PH_GPIO_Port, HRTIM_CHC2_PH_Pin, phase);
    //End High HRTIM CHC

    //High Resolution Timer CHD
		// set the sign of the move (phase)
	if(cmd_ref[HRD1] < 0){
		phase = GPIO_PIN_RESET; // reverse direction
	} else {
		phase = GPIO_PIN_SET; //forward direction
	}
	HAL_GPIO_WritePin(HRTIM_CHD1_PH_GPIO_Port, HRTIM_CHD1_PH_Pin, phase);

// set the sign of the move (phase)
	if(cmd_ref[HRD2] < 0){
		phase = GPIO_PIN_RESET; // reverse direction
	} else {
		phase = GPIO_PIN_SET; //forward direction
	}
	HAL_GPIO_WritePin(HRTIM_CHD2_PH_GPIO_Port, HRTIM_CHD2_PH_Pin, phase);
    //End High HRTIM CHD
     //END HRTIM CODE

    //Low Power Timer
	// set the sign of the move (phase)
	if(cmd_ref[LPTIM] < 0){
		phase = GPIO_PIN_RESET; // reverse direction
	} else {
		phase = GPIO_PIN_SET; //forward direction
	}
	HAL_GPIO_WritePin(LPTIM1_OUT_PH_GPIO_Port, LPTIM1_OUT_PH_Pin, phase);
    //End low power timer

//	}

	//Timer 1
	// calculate the dutycycle
	absref = fabs(cmd_ref[T1C1]); // duty cycle must be positive
	dutycycle = calc_dutycycle(absref,VSS);
	TIM1->CCR1 = dutycycle;   //Calls the duty cycle on the timers at the desired channel

	absref = fabs(cmd_ref[T1C2]); // duty cycle must be positive
	dutycycle = calc_dutycycle(absref,VSS);
	TIM1->CCR2 = dutycycle;

	absref = fabs(cmd_ref[T1C3]); // duty cycle must be positive
	dutycycle = calc_dutycycle(absref,VSS);
	TIM1->CCR3 = dutycycle;

	absref = fabs(cmd_ref[T1C4]); // duty cycle must be positive
	dutycycle = calc_dutycycle(absref,VSS);
	TIM1->CCR4 = dutycycle;
	//End Timer 1

	//Timer 2
	absref = fabs(cmd_ref[T2C1]); // duty cycle must be positive
	dutycycle = calc_dutycycle(absref,VSS);
	TIM2->CCR1 = dutycycle;
	//End Timer 2

	//Timer 4
	absref = fabs(cmd_ref[T4C1]); // duty cycle must be positive
	dutycycle = calc_dutycycle(absref,VSS);
	TIM4->CCR1 = dutycycle;

	absref = fabs(cmd_ref[T4C2]); // duty cycle must be positive
	dutycycle = calc_dutycycle(absref,VSS);
	TIM4->CCR2 = dutycycle;

	absref = fabs(cmd_ref[T4C3]); // duty cycle must be positive
	dutycycle = calc_dutycycle(absref,VSS);
	TIM4->CCR3 = dutycycle;

	absref = fabs(cmd_ref[T4C4]); // duty cycle must be positive
	dutycycle = calc_dutycycle(absref,VSS);
	TIM4->CCR4 = dutycycle;
	//End Timer 4

	//Timer 5
	absref = fabs(cmd_ref[T5C2]); // duty cycle must be positive
	dutycycle = calc_dutycycle(absref,VSS);
	TIM5->CCR2 = dutycycle;

	absref = fabs(cmd_ref[T5C3]); // duty cycle must be positive
	dutycycle = calc_dutycycle(absref,VSS);
	TIM5->CCR3 = dutycycle;
	//End Timer 5

	//Timer 8
	absref = fabs(cmd_ref[T8C4]); // duty cycle must be positive
	dutycycle = calc_dutycycle(absref,VSS);
	TIM8->CCR4 = dutycycle;
	//End Timer 8

	//Timer 12
	absref = fabs(cmd_ref[T12C2]); // duty cycle must be positive
	dutycycle = calc_dutycycle(absref,VSS);
	TIM12->CCR2 = dutycycle;
	//End Timer 12

	//Timer 13
	absref = fabs(cmd_ref[T13C1]); // duty cycle must be positive
	dutycycle = calc_dutycycle(absref,VSS);
	TIM13->CCR1 = dutycycle;
	//End Timer 13

	//Timer 14
	absref = fabs(cmd_ref[T14C1]); // duty cycle must be positive
	dutycycle = calc_dutycycle(absref,VSS);
	TIM14->CCR1 = dutycycle;
	//End Timer 14

	//Timer 15
	absref = fabs(cmd_ref[T15C1]); // duty cycle must be positive
	dutycycle = calc_dutycycle(absref,VSS);
	TIM15->CCR1 = dutycycle;

	absref = fabs(cmd_ref[T15C2]); // duty cycle must be positive
	dutycycle = calc_dutycycle(absref,VSS);
	TIM15->CCR2 = dutycycle;
	//End Timer 15

	//Timer 16
	absref = fabs(cmd_ref[T16C1]); // duty cycle must be positive
	dutycycle = calc_dutycycle(absref,VSS);
	TIM16->CCR1 = dutycycle;
	//End Timer 16

	//HRTIM CODE GOES HERE ********
	//HRTIM CHA
	absref = fabs(cmd_ref[HRA1]); // duty cycle must be positive
	dutycycle = calc_dutycycle(absref,VSS);
	HRTIM1->sTimerxRegs[HRTIM_TIMERINDEX_TIMER_A].CMP1xR = dutycycle;

	absref = fabs(cmd_ref[HRA2]); // duty cycle must be positive
	dutycycle = calc_dutycycle(absref,VSS);
	HRTIM1->sTimerxRegs[HRTIM_TIMERINDEX_TIMER_A].CMP2xR = dutycycle;
	//End HRTIM CHA

	//HRTIM CHB
	absref = fabs(cmd_ref[HRB1]); // duty cycle must be positive
	dutycycle = calc_dutycycle(absref,VSS);
	HRTIM1->sTimerxRegs[HRTIM_TIMERINDEX_TIMER_B].CMP1xR = dutycycle;

	absref = fabs(cmd_ref[HRB2]); // duty cycle must be positive
	dutycycle = calc_dutycycle(absref,VSS);
	HRTIM1->sTimerxRegs[HRTIM_TIMERINDEX_TIMER_B].CMP2xR = dutycycle;
	//End HRTIM CHB

	//HRTIM CHC
	absref = fabs(cmd_ref[HRC1]); // duty cycle must be positive
	dutycycle = calc_dutycycle(absref,VSS);
	HRTIM1->sTimerxRegs[HRTIM_TIMERINDEX_TIMER_C].CMP1xR = dutycycle;

	absref = fabs(cmd_ref[HRC2]); // duty cycle must be positive
	dutycycle = calc_dutycycle(absref,VSS);
	HRTIM1->sTimerxRegs[HRTIM_TIMERINDEX_TIMER_C].CMP2xR = dutycycle;
	//End HRTIM CHC

	//HRTIM CHD
	absref = fabs(cmd_ref[HRD1]); // duty cycle must be positive
	dutycycle = calc_dutycycle(absref,VSS);
	HRTIM1->sTimerxRegs[HRTIM_TIMERINDEX_TIMER_D].CMP1xR = dutycycle;

	absref = fabs(cmd_ref[HRD2]); // duty cycle must be positive
	dutycycle = calc_dutycycle(absref,VSS);
	HRTIM1->sTimerxRegs[HRTIM_TIMERINDEX_TIMER_D].CMP2xR = dutycycle;
	//End HRTIM CHD
	//END HRTIM CODE HERE

	//LPTIM1
	absref = fabs(cmd_ref[LPTIM]); // duty cycle must be positive
	dutycycle = calc_dutycycle(absref,VSS);
	LPTIM1->CMP = dutycycle/2;
	//End LPTIM1

	// reset timer flag
	ctrl_tmr_expired = FALSE;
}

//------------------------------//
//	@function calc_dutycycle(cmd, vss)
//	@ param cmd command voltage
//	@ param vss supply voltage
//	@ return dutycycle

static uint16_t calc_dutycycle(uint16_t cmd, double vss)
{
	// duty cycle variable
	uint16_t dc={0};
	double scale = 1.8/15000; // rough calibration of v/nm

	dc = (uint16_t)((cmd*scale)/vss * (double)PERIOD);
	// keep the dutycycle within the period of the PWM signal
	if(dc>PERIOD) dc = PERIOD;

	return dc;
}

static void gen_sine(void)
{
	int i = 0;
	double scale = TWO_PI/SIN_PERIOD;
	for(i=0; i<SIN_PERIOD; i++ )
	{
		sine_vals[i] = sin(i*scale);
	}
}

/* USER CODE END 4 */

 /* MPU Configuration */

void MPU_Config(void)
{

  /* Disables the MPU */
  LL_MPU_Disable();

  /** Initializes and configures the Region and the memory to be protected
  */
  LL_MPU_ConfigRegion(LL_MPU_REGION_NUMBER0, 0x87, 0x0, LL_MPU_REGION_SIZE_4GB|LL_MPU_TEX_LEVEL0|LL_MPU_REGION_NO_ACCESS|LL_MPU_INSTRUCTION_ACCESS_DISABLE|LL_MPU_ACCESS_SHAREABLE|LL_MPU_ACCESS_NOT_CACHEABLE|LL_MPU_ACCESS_NOT_BUFFERABLE);
  /* Enables the MPU */
  LL_MPU_Enable(LL_MPU_CTRL_PRIVILEGED_DEFAULT);

}

void Error_Handler(void)
{
  __disable_irq();
  while (1)
  {
  }
}

=======
/* USER CODE BEGIN Header */
/**
  ******************************************************************************
  * @file           : main.c
  * @brief          : Main program body
  ******************************************************************************
  * @attention
  *
  * Copyright (c) 2024 STMicroelectronics.
  * All rights reserved.
  *
  * This software is licensed under terms that can be found in the LICENSE file
  * in the root directory of this software component.
  * If no LICENSE file comes with this software, it is provided AS-IS.
  *
  ******************************************************************************
  */
/* USER CODE END Header */
#include "main.h"
#include "stdio.h"
/* USER CODE BEGIN Includes */
#include <math.h>
#include <stdio.h>
/* USER CODE END Includes */

/* USER CODE BEGIN PD */
#define PERIOD 23999
#define SIN_PERIOD 1000 // period of the sin wave in PWM update rates
#define TRUE 1
#define FALSE 0
#define ONESEC 10000
#ifndef M_PI
#define M_PI 3.14159265358979323846
#endif
#define TWO_PI (2*M_PI)

//#define ONESEC 10000

//Used for producing UART output in time-scale instead of timer ticks
#define PERIOD_SCALE (1.0/24000)
#define TICK_SCALE (1.0/240000000)

//Defines for circular buffer
#define BUFFER_LENGTH 100
#define MESSAGE_LENGTH 100

//Define for command length to populate command array
#define CMD_LENGTH 27*2

/* USER CODE END PD */

HRTIM_HandleTypeDef hhrtim;

LPTIM_HandleTypeDef hlptim1;

TIM_HandleTypeDef htim1;
TIM_HandleTypeDef htim2;
TIM_HandleTypeDef htim4;
TIM_HandleTypeDef htim5;
TIM_HandleTypeDef htim8;
TIM_HandleTypeDef htim12;
TIM_HandleTypeDef htim13;
TIM_HandleTypeDef htim14;
TIM_HandleTypeDef htim15;
TIM_HandleTypeDef htim16;

UART_HandleTypeDef huart4;

/* USER CODE BEGIN PV */
static const double VSS = 1.8; // fixed by PCB design
char msg[80];
int msg_length;
uint8_t ctrl_tmr_expired = FALSE; //controller update flag
static double ref=0;// reference (input) for control loop
static double sine_vals[SIN_PERIOD] = {0};

//Variables for UART Output to Check Initialization Times
static long long int sys_timer = 0;
char message[64] = {'\0'};

//Counter for UART Output in Time-Scale
	static long int period_ticks = 0;
	char buffer[64];

	float read_TIM1_sec(){
		float time = 0;
		time = period_ticks * PERIOD_SCALE + TIM1->CNT * TICK_SCALE;
		return time;
	}

//Counter for UART Output in clock ticks
		uint64_t read_TIM1() {
		//return TIM1->CNT;
		 return TIM1->CNT + sys_timer;
	  }

//Flag for UART Transmit and Receive
		static uint8_t data_ready = FALSE;

		struct circular_buffer {
		    int read_index;
		    int write_index;
		    int size;
		    unsigned char data[BUFFER_LENGTH];
		}; /*circular  buffer */

		struct circular_buffer rx_buffer; /*Circular UART RX buffer */
		struct circular_buffer *rxp = &rx_buffer;

		//static int8_t rx_collision = FALSE;
		static int8_t reading_rx_buffer = FALSE;

		//Used to echo elements in circular buffer back to putty
		uint8_t circ_buff_message[BUFFER_LENGTH]= {'\0'};
		static int8_t index = 0;

		//Flags and arrays to send a command ready flag
		static uint8_t cmd_ready = FALSE;
		static uint8_t num = 0;

/* USER CODE END PV */

void SystemClock_Config(void);
static void MPU_Config(void);
static void MX_GPIO_Init(void);
static void MX_TIM1_Init(void);
static void MX_TIM2_Init(void);
static void MX_TIM4_Init(void);
static void MX_TIM5_Init(void);
static void MX_TIM8_Init(void);
static void MX_TIM12_Init(void);
static void MX_TIM13_Init(void);
static void MX_TIM14_Init(void);
static void MX_TIM15_Init(void);
static void MX_TIM16_Init(void);
static void MX_HRTIM_Init(void);
static void MX_LPTIM1_Init(void);
static void MX_UART4_Init(void);
/* USER CODE BEGIN PFP */
static void control_update(double ref);
static uint16_t calc_dutycycle(double v_in, double vss);
static void gen_sine(void);

//Flags used for UART Communication
void UART_update();
void command_update();

static void init_buffer(struct circular_buffer *buf);
static int8_t is_buffer_empty(struct circular_buffer *buf);
static int8_t is_buffer_full(struct circular_buffer *buf);
static int8_t write_buffer(struct circular_buffer *buf, unsigned char c);
static unsigned char read_from_buffer(struct circular_buffer *buf);
static int get_num_elements(struct circular_buffer *buf);

/* USER CODE END PFP */

/* USER CODE BEGIN 0 */
//Variables to test UART Receive & Transmission with IT
	static uint8_t rx_buff[1];

/* USER CODE END 0 */

int main(void)
{

  /* MPU Configuration--------------------------------------------------------*/
  MPU_Config();

  /* MCU Configuration--------------------------------------------------------*/

  /* Reset of all peripherals, Initializes the Flash interface and the Systick. */
  HAL_Init();

  /* Configure the system clock */
  SystemClock_Config();

  /* Initialize all configured peripherals */
  MX_GPIO_Init();
  MX_TIM1_Init();
  MX_TIM2_Init();
  MX_TIM4_Init();
  MX_TIM5_Init();
  MX_TIM8_Init();
  MX_TIM12_Init();
  MX_TIM13_Init();
  MX_TIM14_Init();
  MX_TIM15_Init();
  MX_TIM16_Init();
  MX_HRTIM_Init();
  MX_LPTIM1_Init();
  MX_UART4_Init();
  /* USER CODE BEGIN 2 */

  //Timer 1
  HAL_TIM_Base_Start_IT(&htim1);
  HAL_TIM_PWM_Start(&htim1, TIM_CHANNEL_1);    //Starts the PWM on each of the desired channels
  HAL_TIM_PWM_Start(&htim1, TIM_CHANNEL_2);
  HAL_TIM_PWM_Start(&htim1, TIM_CHANNEL_3);
  HAL_TIM_PWM_Start(&htim1, TIM_CHANNEL_4);
  HAL_GPIO_WritePin(TIM1_CH1_PH_GPIO_Port, TIM1_CH1_PH_Pin, GPIO_PIN_SET);   //Sets the pin to 1
  HAL_GPIO_WritePin(TIM1_CH2_PH_GPIO_Port, TIM1_CH2_PH_Pin, GPIO_PIN_SET);
  HAL_GPIO_WritePin(TIM1_CH3_PH_GPIO_Port, TIM1_CH3_PH_Pin, GPIO_PIN_SET);
  HAL_GPIO_WritePin(TIM1_CH4_PH_GPIO_Port, TIM1_CH4_PH_Pin, GPIO_PIN_SET);
/*
			//Timer 1 Init. Message Over UART
			sprintf(message, "Tim1 Init: %d \n\r", read_TIM1());
			HAL_UART_Transmit(&huart4, (uint8_t*)message, sizeof(message), 100);

  	  	  	sprintf(buffer, "Tim1 sec: %e \n\r", read_TIM1_sec());
  			HAL_UART_Transmit(&huart4, (uint8_t*)buffer, sizeof(buffer), HAL_MAX_DELAY);
  			sprintf(buffer, "Tim1 Cnt: %d \n\r", TIM1->CNT);
  			HAL_UART_Transmit(&huart4, (uint8_t*)buffer, sizeof(buffer), HAL_MAX_DELAY);
  			sprintf(buffer, "Per Cnt: %d \n\r", period_ticks);
  			HAL_UART_Transmit(&huart4, (uint8_t*)buffer, sizeof(buffer), HAL_MAX_DELAY);
  			//End UART Transmit
  			 *
  			 */
  //End Timer 1

  //Timer 2
  HAL_TIM_Base_Start_IT(&htim2);
  HAL_TIM_PWM_Start(&htim2, TIM_CHANNEL_1);
  HAL_GPIO_WritePin(TIM2_CH1_PH_GPIO_Port, TIM2_CH1_PH_Pin, GPIO_PIN_SET);
/*
  	  	  	//Timer 2 Init. Message Over UART
  			sprintf(message, "Tim2 Init: %d \n\r", read_TIM1());
  			HAL_UART_Transmit(&huart4, (uint8_t*)message, sizeof(message), 100);

  	  	  	sprintf(buffer, "Tim2 sec: %e \n\r", read_TIM1_sec());
    		HAL_UART_Transmit(&huart4, (uint8_t*)buffer, sizeof(buffer), HAL_MAX_DELAY);
    		sprintf(buffer, "Tim1 Cnt: %d \n\r", TIM1->CNT);
    		HAL_UART_Transmit(&huart4, (uint8_t*)buffer, sizeof(buffer), HAL_MAX_DELAY);
    		sprintf(buffer, "Per Cnt: %d \n\r", period_ticks);
    		HAL_UART_Transmit(&huart4, (uint8_t*)buffer, sizeof(buffer), HAL_MAX_DELAY);
    		//End UART Transmit
    		 *
    		 */
  //End Timer 2

  //Timer 4
  HAL_TIM_Base_Start_IT(&htim4);
  HAL_TIM_PWM_Start(&htim4, TIM_CHANNEL_1);
  HAL_TIM_PWM_Start(&htim4, TIM_CHANNEL_2);
  HAL_TIM_PWM_Start(&htim4, TIM_CHANNEL_3);
  HAL_TIM_PWM_Start(&htim4, TIM_CHANNEL_4);
  HAL_GPIO_WritePin(TIM4_CH1_PH_GPIO_Port, TIM4_CH1_PH_Pin, GPIO_PIN_SET);
  HAL_GPIO_WritePin(TIM4_CH2_PH_GPIO_Port, TIM4_CH2_PH_Pin, GPIO_PIN_SET);
  HAL_GPIO_WritePin(TIM4_CH3_PH_GPIO_Port, TIM4_CH3_PH_Pin, GPIO_PIN_SET);
  HAL_GPIO_WritePin(TIM4_CH4_PH_GPIO_Port, TIM4_CH4_PH_Pin, GPIO_PIN_SET);
/*
  	  	  	  //Timer 4 Init. Message Over UART
    		  sprintf(message, "Tim4 Init: %d \n\r", read_TIM1());
    		  HAL_UART_Transmit(&huart4, (uint8_t*)message, sizeof(message), 100);

  	  	  	  sprintf(buffer, "Tim4 sec: %e \n\r", read_TIM1_sec());
      		  HAL_UART_Transmit(&huart4, (uint8_t*)buffer, sizeof(buffer), HAL_MAX_DELAY);
      		  sprintf(buffer, "Tim1 Cnt: %d \n\r", TIM1->CNT);
      		  HAL_UART_Transmit(&huart4, (uint8_t*)buffer, sizeof(buffer), HAL_MAX_DELAY);
      		  sprintf(buffer, "Per Cnt: %d \n\r", period_ticks);
      		  HAL_UART_Transmit(&huart4, (uint8_t*)buffer, sizeof(buffer), HAL_MAX_DELAY);
      		  //End UART Transmit
      		   *
      		   */
  //End Timer 4

  //Timer 5
  HAL_TIM_Base_Start_IT(&htim5);
  HAL_TIM_PWM_Start(&htim5, TIM_CHANNEL_2);
  HAL_TIM_PWM_Start(&htim5, TIM_CHANNEL_3);
  HAL_GPIO_WritePin(TIM5_CH2_PH_GPIO_Port, TIM5_CH2_PH_Pin, GPIO_PIN_SET);
  HAL_GPIO_WritePin(TIM5_CH3_PH_GPIO_Port, TIM5_CH3_PH_Pin, GPIO_PIN_SET);
/*
  	  	  	  //Timer 5 Init. Message Over UART
      		  sprintf(message, "Tim5 Init: %d \n\r", read_TIM1());
      		  HAL_UART_Transmit(&huart4, (uint8_t*)message, sizeof(message), 100);

  	  	  	  sprintf(buffer, "Tim5 sec: %e \n\r", read_TIM1_sec());
        	  HAL_UART_Transmit(&huart4, (uint8_t*)buffer, sizeof(buffer), HAL_MAX_DELAY);
        	  sprintf(buffer, "Tim1 Cnt: %d \n\r", TIM1->CNT);
        	  HAL_UART_Transmit(&huart4, (uint8_t*)buffer, sizeof(buffer), HAL_MAX_DELAY);
        	  sprintf(buffer, "Per Cnt: %d \n\r", period_ticks);
        	  HAL_UART_Transmit(&huart4, (uint8_t*)buffer, sizeof(buffer), HAL_MAX_DELAY);
        	  //End UART Transmit
        	   *
        	   */
  //End Timer 5

  //Timer 8
  HAL_TIM_Base_Start_IT(&htim8);
  HAL_TIM_PWM_Start(&htim8, TIM_CHANNEL_4);
  HAL_GPIO_WritePin(TIM8_CH4_PH_GPIO_Port, TIM8_CH4_PH_Pin, GPIO_PIN_SET);
/*
  	  	  	  //Timer 8 Init. Message Over UART
        	  sprintf(message, "Tim8 Init: %d \n\r", read_TIM1());
        	  HAL_UART_Transmit(&huart4, (uint8_t*)message, sizeof(message), 100);
        	  //End UART Transmit
        	   *
        	   */
  //End Timer 8

  //Timer 12
  HAL_TIM_Base_Start_IT(&htim12);
  HAL_TIM_PWM_Start(&htim12, TIM_CHANNEL_2);
  HAL_GPIO_WritePin(TIM12_CH2_PH_GPIO_Port, TIM12_CH2_PH_Pin, GPIO_PIN_SET);
/*
  	  	  	  //Timer 12 Init. Message Over UART
         	  sprintf(message, "Tim12 Init: %d \n\r", read_TIM1());
         	  HAL_UART_Transmit(&huart4, (uint8_t*)message, sizeof(message), 100);
         	  //End UART Transmit
         	   *
         	   */
  //End Timer 12

  //Timer 13
  HAL_TIM_Base_Start_IT(&htim13);
  HAL_TIM_PWM_Start(&htim13, TIM_CHANNEL_1);
  HAL_GPIO_WritePin(TIM13_CH1_PH_GPIO_Port, TIM13_CH1_PH_Pin, GPIO_PIN_SET);
/*
  	  	  	  //Timer 13 Init. Message Over UART
           	  sprintf(message, "Tim13 Init: %d \n\r", read_TIM1());
           	  HAL_UART_Transmit(&huart4, (uint8_t*)message, sizeof(message), 100);
           	  //End UART Transmit
           	   *
           	   */
  //End Timer 13

  //Timer 14
  HAL_TIM_Base_Start_IT(&htim14);
  HAL_TIM_PWM_Start(&htim14, TIM_CHANNEL_1);
  HAL_GPIO_WritePin(TIM14_CH1_PH_GPIO_Port, TIM14_CH1_PH_Pin, GPIO_PIN_SET);
/*
  	  	  	  //Timer 14 Init. Message Over UART
           	  sprintf(message, "Tim14 Init: %d \n\r", read_TIM1());
           	  HAL_UART_Transmit(&huart4, (uint8_t*)message, sizeof(message), 100);
           	  //End UART Transmit
           	   *
           	   */
  //End Timer 14

  //Timer 15
  HAL_TIM_Base_Start_IT(&htim15);
  HAL_TIM_PWM_Start(&htim15, TIM_CHANNEL_1);
  HAL_TIM_PWM_Start(&htim15, TIM_CHANNEL_2);
  HAL_GPIO_WritePin(TIM15_CH1_PH_GPIO_Port, TIM15_CH1_PH_Pin, GPIO_PIN_SET);
  HAL_GPIO_WritePin(TIM15_CH2_PH_GPIO_Port, TIM15_CH2_PH_Pin, GPIO_PIN_SET);
/*
  	  	  	  //Timer 15 Init. Message Over UART
           	  sprintf(message, "Tim15 Init: %d \n\r", read_TIM1());
           	  HAL_UART_Transmit(&huart4, (uint8_t*)message, sizeof(message), 100);
           	  //End UART Transmit\
           	   *
           	   */
  //End Timer 15

  //Timer 16
  HAL_TIM_Base_Start_IT(&htim16);
  HAL_TIM_PWM_Start(&htim16, TIM_CHANNEL_1);
  HAL_GPIO_WritePin(TIM16_CH1_PH_GPIO_Port, TIM16_CH1_PH_Pin, GPIO_PIN_SET);
/*
  	  	  	  //Timer 16 Init. Message Over UART
              sprintf(message, "Tim16 Init: %d \n\r", read_TIM1());
              HAL_UART_Transmit(&huart4, (uint8_t*)message, sizeof(message), 100);
              //End UART Transmit
               *
               */
  //End Timer 16

  //HRTIM CODE GOES HERE *******
     // Enable output
     HRTIM1->sCommonRegs.OENR = HRTIM_OENR_TA1OEN + HRTIM_OENR_TA2OEN +
     	 	HRTIM_OENR_TB1OEN + HRTIM_OENR_TB2OEN + HRTIM_OENR_TC1OEN + HRTIM_OENR_TC2OEN + HRTIM_OENR_TD1OEN + HRTIM_OENR_TD2OEN;
     //Start Timer
     HRTIM1->sMasterRegs.MCR = HRTIM_MCR_TACEN + HRTIM_MCR_TBCEN + HRTIM_MCR_TCCEN + HRTIM_MCR_TDCEN;
/*
     	 	 //HRTIM Init. Message Over UART
             sprintf(message, "HRTIM Init: %d \n\r", read_TIM1());
             HAL_UART_Transmit(&huart4, (uint8_t*)message, sizeof(message), 100);
             //End UART Transmit
              *
              */
  //END HRTIM CODE

  //Low-Power Timer
     HAL_LPTIM_Counter_Start_IT(&hlptim1, LPTIM_ARR_ARR);
     HAL_LPTIM_PWM_Start(&hlptim1, LPTIM_ARR_ARR, LPTIM_CMP_CMP);
     HAL_GPIO_WritePin(LPTIM1_OUT_PH_GPIO_Port, LPTIM1_OUT_PH_Pin, GPIO_PIN_SET);
       	LPTIM1->ARR = (12000-1);
/*
       		//LPTIM Init. Message Over UART
       	    sprintf(message, "LPTIM Init: %d \n\r", read_TIM1());
       	    HAL_UART_Transmit(&huart4, (uint8_t*)message, sizeof(message), 100);
       	    //End UART Transmit
       	     */
  //End Low Power Timer

       	    //Timer Synchronization
       	    TIM1->CNT = 0;
       	    TIM2->CNT = 0;
       	    TIM4->CNT = 0;
       	    TIM5->CNT = 0;
       	    TIM8->CNT = 0;
       	    TIM12->CNT = 0;
       	    TIM13->CNT = 0;
       	    TIM14->CNT = 0;
       	    TIM15->CNT = 0;
       	    TIM16->CNT = 0;
       	    LPTIM1->CNT = 0;

   gen_sine();

  /* USER CODE END 2 */

  /* Infinite loop */
  /* USER CODE BEGIN WHILE */
   init_buffer(rxp);
   HAL_UART_Receive_IT(&huart4, rx_buff, sizeof(rx_buff));

  while (1)
  {
	  if(ctrl_tmr_expired == TRUE) control_update(ref); 	//Sets flag for timer inturrupt
	  if(data_ready == TRUE) UART_update(); 	//Sets flag when a message is received
	  if(cmd_ready == TRUE) command_update(); 	//Sets flag once message is ready to send

    /* USER CODE END WHILE */

  }
}

void SystemClock_Config(void)
{
  RCC_OscInitTypeDef RCC_OscInitStruct = {0};
  RCC_ClkInitTypeDef RCC_ClkInitStruct = {0};

  /** Supply configuration update enable
  */
  HAL_PWREx_ConfigSupply(PWR_LDO_SUPPLY);

  /** Configure the main internal regulator output voltage
  */
  __HAL_PWR_VOLTAGESCALING_CONFIG(PWR_REGULATOR_VOLTAGE_SCALE1);

  while(!__HAL_PWR_GET_FLAG(PWR_FLAG_VOSRDY)) {}

  __HAL_RCC_SYSCFG_CLK_ENABLE();
  __HAL_PWR_VOLTAGESCALING_CONFIG(PWR_REGULATOR_VOLTAGE_SCALE0);

  while(!__HAL_PWR_GET_FLAG(PWR_FLAG_VOSRDY)) {}

  /** Initializes the RCC Oscillators according to the specified parameters
  * in the RCC_OscInitTypeDef structure.
  */
  RCC_OscInitStruct.OscillatorType = RCC_OSCILLATORTYPE_HSE;
  RCC_OscInitStruct.HSEState = RCC_HSE_ON;
  RCC_OscInitStruct.PLL.PLLState = RCC_PLL_ON;
  RCC_OscInitStruct.PLL.PLLSource = RCC_PLLSOURCE_HSE;
  RCC_OscInitStruct.PLL.PLLM = 2;
  RCC_OscInitStruct.PLL.PLLN = 80;
  RCC_OscInitStruct.PLL.PLLP = 2;
  RCC_OscInitStruct.PLL.PLLQ = 2;
  RCC_OscInitStruct.PLL.PLLR = 2;
  RCC_OscInitStruct.PLL.PLLRGE = RCC_PLL1VCIRANGE_3;
  RCC_OscInitStruct.PLL.PLLVCOSEL = RCC_PLL1VCOWIDE;
  RCC_OscInitStruct.PLL.PLLFRACN = 0;
  if (HAL_RCC_OscConfig(&RCC_OscInitStruct) != HAL_OK)
  {
    Error_Handler();
  }

  /** Initializes the CPU, AHB and APB buses clocks
  */
  RCC_ClkInitStruct.ClockType = RCC_CLOCKTYPE_HCLK|RCC_CLOCKTYPE_SYSCLK
                              |RCC_CLOCKTYPE_PCLK1|RCC_CLOCKTYPE_PCLK2
                              |RCC_CLOCKTYPE_D3PCLK1|RCC_CLOCKTYPE_D1PCLK1;
  RCC_ClkInitStruct.SYSCLKSource = RCC_SYSCLKSOURCE_PLLCLK;
  RCC_ClkInitStruct.SYSCLKDivider = RCC_SYSCLK_DIV1;
  RCC_ClkInitStruct.AHBCLKDivider = RCC_HCLK_DIV2;
  RCC_ClkInitStruct.APB3CLKDivider = RCC_APB3_DIV2;
  RCC_ClkInitStruct.APB1CLKDivider = RCC_APB1_DIV2;
  RCC_ClkInitStruct.APB2CLKDivider = RCC_APB2_DIV2;
  RCC_ClkInitStruct.APB4CLKDivider = RCC_APB4_DIV2;

  if (HAL_RCC_ClockConfig(&RCC_ClkInitStruct, FLASH_LATENCY_4) != HAL_OK)
  {
    Error_Handler();
  }
}

static void MX_HRTIM_Init(void)
{

  HRTIM_EventCfgTypeDef pEventCfg = {0};
  HRTIM_TimeBaseCfgTypeDef pTimeBaseCfg = {0};
  HRTIM_TimerCfgTypeDef pTimerCfg = {0};
  HRTIM_CompareCfgTypeDef pCompareCfg = {0};
  HRTIM_OutputCfgTypeDef pOutputCfg = {0};

  hhrtim.Instance = HRTIM1;
  hhrtim.Init.HRTIMInterruptResquests = HRTIM_IT_NONE;
  hhrtim.Init.SyncOptions = HRTIM_SYNCOPTION_NONE;
  if (HAL_HRTIM_Init(&hhrtim) != HAL_OK)
  {
    Error_Handler();
  }
  if (HAL_HRTIM_EventPrescalerConfig(&hhrtim, HRTIM_EVENTPRESCALER_DIV1) != HAL_OK)
  {
    Error_Handler();
  }
  pEventCfg.Source = HRTIM_EVENTSRC_3;
  pEventCfg.Polarity = HRTIM_EVENTPOLARITY_HIGH;
  pEventCfg.Sensitivity = HRTIM_EVENTSENSITIVITY_RISINGEDGE;
  pEventCfg.FastMode = HRTIM_EVENTFASTMODE_DISABLE;
  if (HAL_HRTIM_EventConfig(&hhrtim, HRTIM_EVENT_1, &pEventCfg) != HAL_OK)
  {
    Error_Handler();
  }
  pTimeBaseCfg.Period = 24000-1;
  pTimeBaseCfg.RepetitionCounter = 0x00;
  pTimeBaseCfg.PrescalerRatio = HRTIM_PRESCALERRATIO_DIV1;
  pTimeBaseCfg.Mode = HRTIM_MODE_CONTINUOUS;
  if (HAL_HRTIM_TimeBaseConfig(&hhrtim, HRTIM_TIMERINDEX_TIMER_A, &pTimeBaseCfg) != HAL_OK)
  {
    Error_Handler();
  }
  pTimerCfg.InterruptRequests = HRTIM_TIM_IT_NONE;
  pTimerCfg.DMARequests = HRTIM_TIM_DMA_NONE;
  pTimerCfg.DMASrcAddress = 0x0000;
  pTimerCfg.DMADstAddress = 0x0000;
  pTimerCfg.DMASize = 0x1;
  pTimerCfg.HalfModeEnable = HRTIM_HALFMODE_DISABLED;
  pTimerCfg.StartOnSync = HRTIM_SYNCSTART_DISABLED;
  pTimerCfg.ResetOnSync = HRTIM_SYNCRESET_DISABLED;
  pTimerCfg.DACSynchro = HRTIM_DACSYNC_NONE;
  pTimerCfg.PreloadEnable = HRTIM_PRELOAD_ENABLED;
  pTimerCfg.UpdateGating = HRTIM_UPDATEGATING_INDEPENDENT;
  pTimerCfg.BurstMode = HRTIM_TIMERBURSTMODE_MAINTAINCLOCK;
  pTimerCfg.RepetitionUpdate = HRTIM_UPDATEONREPETITION_DISABLED;
  pTimerCfg.PushPull = HRTIM_TIMPUSHPULLMODE_DISABLED;
  pTimerCfg.FaultEnable = HRTIM_TIMFAULTENABLE_NONE;
  pTimerCfg.FaultLock = HRTIM_TIMFAULTLOCK_READWRITE;
  pTimerCfg.DeadTimeInsertion = HRTIM_TIMDEADTIMEINSERTION_DISABLED;
  pTimerCfg.DelayedProtectionMode = HRTIM_TIMER_A_B_C_DELAYEDPROTECTION_DISABLED;
  pTimerCfg.UpdateTrigger = HRTIM_TIMUPDATETRIGGER_NONE;
  pTimerCfg.ResetTrigger = HRTIM_TIMRESETTRIGGER_EEV_1;
  pTimerCfg.ResetUpdate = HRTIM_TIMUPDATEONRESET_ENABLED;
  if (HAL_HRTIM_WaveformTimerConfig(&hhrtim, HRTIM_TIMERINDEX_TIMER_A, &pTimerCfg) != HAL_OK)
  {
    Error_Handler();
  }
  if (HAL_HRTIM_WaveformTimerConfig(&hhrtim, HRTIM_TIMERINDEX_TIMER_B, &pTimerCfg) != HAL_OK)
  {
    Error_Handler();
  }
  if (HAL_HRTIM_WaveformTimerConfig(&hhrtim, HRTIM_TIMERINDEX_TIMER_C, &pTimerCfg) != HAL_OK)
  {
    Error_Handler();
  }
  pTimerCfg.DelayedProtectionMode = HRTIM_TIMER_D_E_DELAYEDPROTECTION_DISABLED;
  if (HAL_HRTIM_WaveformTimerConfig(&hhrtim, HRTIM_TIMERINDEX_TIMER_D, &pTimerCfg) != HAL_OK)
  {
    Error_Handler();
  }
  pCompareCfg.CompareValue = 0x00005A00/2;
  if (HAL_HRTIM_WaveformCompareConfig(&hhrtim, HRTIM_TIMERINDEX_TIMER_A, HRTIM_COMPAREUNIT_1, &pCompareCfg) != HAL_OK)
  {
    Error_Handler();
  }
  pCompareCfg.AutoDelayedMode = HRTIM_AUTODELAYEDMODE_REGULAR;
  pCompareCfg.AutoDelayedTimeout = 0x0000;

  if (HAL_HRTIM_WaveformCompareConfig(&hhrtim, HRTIM_TIMERINDEX_TIMER_A, HRTIM_COMPAREUNIT_2, &pCompareCfg) != HAL_OK)
  {
    Error_Handler();
  }

  if (HAL_HRTIM_WaveformCompareConfig(&hhrtim, HRTIM_TIMERINDEX_TIMER_B, HRTIM_COMPAREUNIT_2, &pCompareCfg) != HAL_OK)
  {
    Error_Handler();
  }

  if (HAL_HRTIM_WaveformCompareConfig(&hhrtim, HRTIM_TIMERINDEX_TIMER_C, HRTIM_COMPAREUNIT_2, &pCompareCfg) != HAL_OK)
  {
    Error_Handler();
  }

  if (HAL_HRTIM_WaveformCompareConfig(&hhrtim, HRTIM_TIMERINDEX_TIMER_D, HRTIM_COMPAREUNIT_2, &pCompareCfg) != HAL_OK)
  {
    Error_Handler();
  }
  pOutputCfg.Polarity = HRTIM_OUTPUTPOLARITY_HIGH;
  pOutputCfg.SetSource = HRTIM_OUTPUTSET_EEV_1|HRTIM_OUTPUTSET_TIMPER;
  pOutputCfg.ResetSource = HRTIM_OUTPUTRESET_TIMCMP1;
  pOutputCfg.IdleMode = HRTIM_OUTPUTIDLEMODE_NONE;
  pOutputCfg.IdleLevel = HRTIM_OUTPUTIDLELEVEL_INACTIVE;
  pOutputCfg.FaultLevel = HRTIM_OUTPUTFAULTLEVEL_NONE;
  pOutputCfg.ChopperModeEnable = HRTIM_OUTPUTCHOPPERMODE_DISABLED;
  pOutputCfg.BurstModeEntryDelayed = HRTIM_OUTPUTBURSTMODEENTRY_REGULAR;
  if (HAL_HRTIM_WaveformOutputConfig(&hhrtim, HRTIM_TIMERINDEX_TIMER_A, HRTIM_OUTPUT_TA1, &pOutputCfg) != HAL_OK)
  {
    Error_Handler();
  }
  if (HAL_HRTIM_WaveformOutputConfig(&hhrtim, HRTIM_TIMERINDEX_TIMER_B, HRTIM_OUTPUT_TB1, &pOutputCfg) != HAL_OK)
  {
    Error_Handler();
  }
  if (HAL_HRTIM_WaveformOutputConfig(&hhrtim, HRTIM_TIMERINDEX_TIMER_C, HRTIM_OUTPUT_TC1, &pOutputCfg) != HAL_OK)
  {
    Error_Handler();
  }
  if (HAL_HRTIM_WaveformOutputConfig(&hhrtim, HRTIM_TIMERINDEX_TIMER_D, HRTIM_OUTPUT_TD1, &pOutputCfg) != HAL_OK)
  {
    Error_Handler();
  }
  pOutputCfg.ResetSource = HRTIM_OUTPUTRESET_TIMCMP2;
  if (HAL_HRTIM_WaveformOutputConfig(&hhrtim, HRTIM_TIMERINDEX_TIMER_A, HRTIM_OUTPUT_TA2, &pOutputCfg) != HAL_OK)
  {
    Error_Handler();
  }
  if (HAL_HRTIM_WaveformOutputConfig(&hhrtim, HRTIM_TIMERINDEX_TIMER_B, HRTIM_OUTPUT_TB2, &pOutputCfg) != HAL_OK)
  {
    Error_Handler();
  }
  if (HAL_HRTIM_WaveformOutputConfig(&hhrtim, HRTIM_TIMERINDEX_TIMER_C, HRTIM_OUTPUT_TC2, &pOutputCfg) != HAL_OK)
  {
    Error_Handler();
  }
  if (HAL_HRTIM_WaveformOutputConfig(&hhrtim, HRTIM_TIMERINDEX_TIMER_D, HRTIM_OUTPUT_TD2, &pOutputCfg) != HAL_OK)
  {
    Error_Handler();
  }
  if (HAL_HRTIM_TimeBaseConfig(&hhrtim, HRTIM_TIMERINDEX_TIMER_B, &pTimeBaseCfg) != HAL_OK)
  {
    Error_Handler();
  }
  if (HAL_HRTIM_WaveformCompareConfig(&hhrtim, HRTIM_TIMERINDEX_TIMER_B, HRTIM_COMPAREUNIT_1, &pCompareCfg) != HAL_OK)
  {
    Error_Handler();
  }
  if (HAL_HRTIM_TimeBaseConfig(&hhrtim, HRTIM_TIMERINDEX_TIMER_C, &pTimeBaseCfg) != HAL_OK)
  {
    Error_Handler();
  }
  if (HAL_HRTIM_WaveformCompareConfig(&hhrtim, HRTIM_TIMERINDEX_TIMER_C, HRTIM_COMPAREUNIT_1, &pCompareCfg) != HAL_OK)
  {
    Error_Handler();
  }
  if (HAL_HRTIM_TimeBaseConfig(&hhrtim, HRTIM_TIMERINDEX_TIMER_D, &pTimeBaseCfg) != HAL_OK)
  {
    Error_Handler();
  }
  if (HAL_HRTIM_WaveformCompareConfig(&hhrtim, HRTIM_TIMERINDEX_TIMER_D, HRTIM_COMPAREUNIT_1, &pCompareCfg) != HAL_OK)
  {
    Error_Handler();
  }
  HAL_HRTIM_MspPostInit(&hhrtim);

}

static void MX_LPTIM1_Init(void)
{

  hlptim1.Instance = LPTIM1;
  hlptim1.Init.Clock.Source = LPTIM_CLOCKSOURCE_APBCLOCK_LPOSC;
  hlptim1.Init.Clock.Prescaler = LPTIM_PRESCALER_DIV1;
  hlptim1.Init.Trigger.Source = LPTIM_TRIGSOURCE_SOFTWARE;
  hlptim1.Init.OutputPolarity = LPTIM_OUTPUTPOLARITY_LOW;
  hlptim1.Init.UpdateMode = LPTIM_UPDATE_IMMEDIATE;
  hlptim1.Init.CounterSource = LPTIM_COUNTERSOURCE_INTERNAL;
  hlptim1.Init.Input1Source = LPTIM_INPUT1SOURCE_GPIO;
  hlptim1.Init.Input2Source = LPTIM_INPUT2SOURCE_GPIO;
  if (HAL_LPTIM_Init(&hlptim1) != HAL_OK)
  {
    Error_Handler();
  }

}

static void MX_TIM1_Init(void)
{

  TIM_ClockConfigTypeDef sClockSourceConfig = {0};
  TIM_MasterConfigTypeDef sMasterConfig = {0};
  TIM_OC_InitTypeDef sConfigOC = {0};
  TIM_BreakDeadTimeConfigTypeDef sBreakDeadTimeConfig = {0};

  htim1.Instance = TIM1;
  htim1.Init.Prescaler = 0;
  htim1.Init.CounterMode = TIM_COUNTERMODE_UP;
  htim1.Init.Period = 24000-1;
  htim1.Init.ClockDivision = TIM_CLOCKDIVISION_DIV1;
  htim1.Init.RepetitionCounter = 0;
  htim1.Init.AutoReloadPreload = TIM_AUTORELOAD_PRELOAD_ENABLE;
  if (HAL_TIM_Base_Init(&htim1) != HAL_OK)
  {
    Error_Handler();
  }
  sClockSourceConfig.ClockSource = TIM_CLOCKSOURCE_INTERNAL;
  if (HAL_TIM_ConfigClockSource(&htim1, &sClockSourceConfig) != HAL_OK)
  {
    Error_Handler();
  }
  if (HAL_TIM_PWM_Init(&htim1) != HAL_OK)
  {
    Error_Handler();
  }
  sMasterConfig.MasterOutputTrigger = TIM_TRGO_UPDATE;
  sMasterConfig.MasterOutputTrigger2 = TIM_TRGO2_RESET;
  sMasterConfig.MasterSlaveMode = TIM_MASTERSLAVEMODE_DISABLE;
  if (HAL_TIMEx_MasterConfigSynchronization(&htim1, &sMasterConfig) != HAL_OK)
  {
    Error_Handler();
  }
  sConfigOC.OCMode = TIM_OCMODE_PWM1;
  sConfigOC.Pulse = 0;
  sConfigOC.OCPolarity = TIM_OCPOLARITY_HIGH;
  sConfigOC.OCNPolarity = TIM_OCNPOLARITY_HIGH;
  sConfigOC.OCFastMode = TIM_OCFAST_DISABLE;
  sConfigOC.OCIdleState = TIM_OCIDLESTATE_RESET;
  sConfigOC.OCNIdleState = TIM_OCNIDLESTATE_RESET;
  if (HAL_TIM_PWM_ConfigChannel(&htim1, &sConfigOC, TIM_CHANNEL_1) != HAL_OK)
  {
    Error_Handler();
  }
  if (HAL_TIM_PWM_ConfigChannel(&htim1, &sConfigOC, TIM_CHANNEL_2) != HAL_OK)
  {
    Error_Handler();
  }
  if (HAL_TIM_PWM_ConfigChannel(&htim1, &sConfigOC, TIM_CHANNEL_3) != HAL_OK)
  {
    Error_Handler();
  }
  if (HAL_TIM_PWM_ConfigChannel(&htim1, &sConfigOC, TIM_CHANNEL_4) != HAL_OK)
  {
    Error_Handler();
  }
  sBreakDeadTimeConfig.OffStateRunMode = TIM_OSSR_DISABLE;
  sBreakDeadTimeConfig.OffStateIDLEMode = TIM_OSSI_DISABLE;
  sBreakDeadTimeConfig.LockLevel = TIM_LOCKLEVEL_OFF;
  sBreakDeadTimeConfig.DeadTime = 0;
  sBreakDeadTimeConfig.BreakState = TIM_BREAK_DISABLE;
  sBreakDeadTimeConfig.BreakPolarity = TIM_BREAKPOLARITY_HIGH;
  sBreakDeadTimeConfig.BreakFilter = 0;
  sBreakDeadTimeConfig.Break2State = TIM_BREAK2_DISABLE;
  sBreakDeadTimeConfig.Break2Polarity = TIM_BREAK2POLARITY_HIGH;
  sBreakDeadTimeConfig.Break2Filter = 0;
  sBreakDeadTimeConfig.AutomaticOutput = TIM_AUTOMATICOUTPUT_DISABLE;
  if (HAL_TIMEx_ConfigBreakDeadTime(&htim1, &sBreakDeadTimeConfig) != HAL_OK)
  {
    Error_Handler();
  }
  HAL_TIM_MspPostInit(&htim1);

}

static void MX_TIM2_Init(void)
{

  TIM_ClockConfigTypeDef sClockSourceConfig = {0};
  TIM_MasterConfigTypeDef sMasterConfig = {0};
  TIM_OC_InitTypeDef sConfigOC = {0};

  htim2.Instance = TIM2;
  htim2.Init.Prescaler = 0;
  htim2.Init.CounterMode = TIM_COUNTERMODE_UP;
  htim2.Init.Period = 24000-1;
  htim2.Init.ClockDivision = TIM_CLOCKDIVISION_DIV1;
  htim2.Init.AutoReloadPreload = TIM_AUTORELOAD_PRELOAD_ENABLE;
  if (HAL_TIM_Base_Init(&htim2) != HAL_OK)
  {
    Error_Handler();
  }
  sClockSourceConfig.ClockSource = TIM_CLOCKSOURCE_INTERNAL;
  if (HAL_TIM_ConfigClockSource(&htim2, &sClockSourceConfig) != HAL_OK)
  {
    Error_Handler();
  }
  if (HAL_TIM_PWM_Init(&htim2) != HAL_OK)
  {
    Error_Handler();
  }
  sMasterConfig.MasterOutputTrigger = TIM_TRGO_RESET;
  sMasterConfig.MasterSlaveMode = TIM_MASTERSLAVEMODE_DISABLE;
  if (HAL_TIMEx_MasterConfigSynchronization(&htim2, &sMasterConfig) != HAL_OK)
  {
    Error_Handler();
  }
  sConfigOC.OCMode = TIM_OCMODE_PWM1;
  sConfigOC.Pulse = 0;
  sConfigOC.OCPolarity = TIM_OCPOLARITY_HIGH;
  sConfigOC.OCFastMode = TIM_OCFAST_DISABLE;
  if (HAL_TIM_PWM_ConfigChannel(&htim2, &sConfigOC, TIM_CHANNEL_1) != HAL_OK)
  {
    Error_Handler();
  }
  HAL_TIM_MspPostInit(&htim2);

}

static void MX_TIM4_Init(void)
{

  TIM_ClockConfigTypeDef sClockSourceConfig = {0};
  TIM_MasterConfigTypeDef sMasterConfig = {0};
  TIM_OC_InitTypeDef sConfigOC = {0};

  htim4.Instance = TIM4;
  htim4.Init.Prescaler = 0;
  htim4.Init.CounterMode = TIM_COUNTERMODE_UP;
  htim4.Init.Period = 24000-1;
  htim4.Init.ClockDivision = TIM_CLOCKDIVISION_DIV1;
  htim4.Init.AutoReloadPreload = TIM_AUTORELOAD_PRELOAD_ENABLE;
  if (HAL_TIM_Base_Init(&htim4) != HAL_OK)
  {
    Error_Handler();
  }
  sClockSourceConfig.ClockSource = TIM_CLOCKSOURCE_INTERNAL;
  if (HAL_TIM_ConfigClockSource(&htim4, &sClockSourceConfig) != HAL_OK)
  {
    Error_Handler();
  }
  if (HAL_TIM_PWM_Init(&htim4) != HAL_OK)
  {
    Error_Handler();
  }
  sMasterConfig.MasterOutputTrigger = TIM_TRGO_RESET;
  sMasterConfig.MasterSlaveMode = TIM_MASTERSLAVEMODE_DISABLE;
  if (HAL_TIMEx_MasterConfigSynchronization(&htim4, &sMasterConfig) != HAL_OK)
  {
    Error_Handler();
  }
  sConfigOC.OCMode = TIM_OCMODE_PWM1;
  sConfigOC.Pulse = 0;
  sConfigOC.OCPolarity = TIM_OCPOLARITY_HIGH;
  sConfigOC.OCFastMode = TIM_OCFAST_DISABLE;
  if (HAL_TIM_PWM_ConfigChannel(&htim4, &sConfigOC, TIM_CHANNEL_1) != HAL_OK)
  {
    Error_Handler();
  }
  if (HAL_TIM_PWM_ConfigChannel(&htim4, &sConfigOC, TIM_CHANNEL_2) != HAL_OK)
  {
    Error_Handler();
  }
  if (HAL_TIM_PWM_ConfigChannel(&htim4, &sConfigOC, TIM_CHANNEL_3) != HAL_OK)
  {
    Error_Handler();
  }
  if (HAL_TIM_PWM_ConfigChannel(&htim4, &sConfigOC, TIM_CHANNEL_4) != HAL_OK)
  {
    Error_Handler();
  }
  HAL_TIM_MspPostInit(&htim4);

}

static void MX_TIM5_Init(void)
{

  TIM_ClockConfigTypeDef sClockSourceConfig = {0};
  TIM_MasterConfigTypeDef sMasterConfig = {0};
  TIM_OC_InitTypeDef sConfigOC = {0};

  htim5.Instance = TIM5;
  htim5.Init.Prescaler = 0;
  htim5.Init.CounterMode = TIM_COUNTERMODE_UP;
  htim5.Init.Period = 24000-1;
  htim5.Init.ClockDivision = TIM_CLOCKDIVISION_DIV1;
  htim5.Init.AutoReloadPreload = TIM_AUTORELOAD_PRELOAD_ENABLE;
  if (HAL_TIM_Base_Init(&htim5) != HAL_OK)
  {
    Error_Handler();
  }
  sClockSourceConfig.ClockSource = TIM_CLOCKSOURCE_INTERNAL;
  if (HAL_TIM_ConfigClockSource(&htim5, &sClockSourceConfig) != HAL_OK)
  {
    Error_Handler();
  }
  if (HAL_TIM_PWM_Init(&htim5) != HAL_OK)
  {
    Error_Handler();
  }
  sMasterConfig.MasterOutputTrigger = TIM_TRGO_RESET;
  sMasterConfig.MasterSlaveMode = TIM_MASTERSLAVEMODE_DISABLE;
  if (HAL_TIMEx_MasterConfigSynchronization(&htim5, &sMasterConfig) != HAL_OK)
  {
    Error_Handler();
  }
  sConfigOC.OCMode = TIM_OCMODE_PWM1;
  sConfigOC.Pulse = 0;
  sConfigOC.OCPolarity = TIM_OCPOLARITY_HIGH;
  sConfigOC.OCFastMode = TIM_OCFAST_DISABLE;
  if (HAL_TIM_PWM_ConfigChannel(&htim5, &sConfigOC, TIM_CHANNEL_2) != HAL_OK)
  {
    Error_Handler();
  }
  if (HAL_TIM_PWM_ConfigChannel(&htim5, &sConfigOC, TIM_CHANNEL_3) != HAL_OK)
  {
    Error_Handler();
  }
  HAL_TIM_MspPostInit(&htim5);

}

static void MX_TIM8_Init(void)
{

  TIM_ClockConfigTypeDef sClockSourceConfig = {0};
  TIM_MasterConfigTypeDef sMasterConfig = {0};
  TIM_OC_InitTypeDef sConfigOC = {0};
  TIM_BreakDeadTimeConfigTypeDef sBreakDeadTimeConfig = {0};

  htim8.Instance = TIM8;
  htim8.Init.Prescaler = 0;
  htim8.Init.CounterMode = TIM_COUNTERMODE_UP;
  htim8.Init.Period = 24000-1;
  htim8.Init.ClockDivision = TIM_CLOCKDIVISION_DIV1;
  htim8.Init.RepetitionCounter = 0;
  htim8.Init.AutoReloadPreload = TIM_AUTORELOAD_PRELOAD_ENABLE;
  if (HAL_TIM_Base_Init(&htim8) != HAL_OK)
  {
    Error_Handler();
  }
  sClockSourceConfig.ClockSource = TIM_CLOCKSOURCE_INTERNAL;
  if (HAL_TIM_ConfigClockSource(&htim8, &sClockSourceConfig) != HAL_OK)
  {
    Error_Handler();
  }
  if (HAL_TIM_PWM_Init(&htim8) != HAL_OK)
  {
    Error_Handler();
  }
  sMasterConfig.MasterOutputTrigger = TIM_TRGO_RESET;
  sMasterConfig.MasterOutputTrigger2 = TIM_TRGO2_RESET;
  sMasterConfig.MasterSlaveMode = TIM_MASTERSLAVEMODE_DISABLE;
  if (HAL_TIMEx_MasterConfigSynchronization(&htim8, &sMasterConfig) != HAL_OK)
  {
    Error_Handler();
  }
  sConfigOC.OCMode = TIM_OCMODE_PWM1;
  sConfigOC.Pulse = 0;
  sConfigOC.OCPolarity = TIM_OCPOLARITY_HIGH;
  sConfigOC.OCFastMode = TIM_OCFAST_DISABLE;
  sConfigOC.OCIdleState = TIM_OCIDLESTATE_RESET;
  sConfigOC.OCNIdleState = TIM_OCNIDLESTATE_RESET;
  if (HAL_TIM_PWM_ConfigChannel(&htim8, &sConfigOC, TIM_CHANNEL_4) != HAL_OK)
  {
    Error_Handler();
  }
  sBreakDeadTimeConfig.OffStateRunMode = TIM_OSSR_DISABLE;
  sBreakDeadTimeConfig.OffStateIDLEMode = TIM_OSSI_DISABLE;
  sBreakDeadTimeConfig.LockLevel = TIM_LOCKLEVEL_OFF;
  sBreakDeadTimeConfig.DeadTime = 0;
  sBreakDeadTimeConfig.BreakState = TIM_BREAK_DISABLE;
  sBreakDeadTimeConfig.BreakPolarity = TIM_BREAKPOLARITY_HIGH;
  sBreakDeadTimeConfig.BreakFilter = 0;
  sBreakDeadTimeConfig.Break2State = TIM_BREAK2_DISABLE;
  sBreakDeadTimeConfig.Break2Polarity = TIM_BREAK2POLARITY_HIGH;
  sBreakDeadTimeConfig.Break2Filter = 0;
  sBreakDeadTimeConfig.AutomaticOutput = TIM_AUTOMATICOUTPUT_DISABLE;
  if (HAL_TIMEx_ConfigBreakDeadTime(&htim8, &sBreakDeadTimeConfig) != HAL_OK)
  {
    Error_Handler();
  }
  HAL_TIM_MspPostInit(&htim8);

}

static void MX_TIM12_Init(void)
{

  TIM_ClockConfigTypeDef sClockSourceConfig = {0};
  TIM_MasterConfigTypeDef sMasterConfig = {0};
  TIM_OC_InitTypeDef sConfigOC = {0};

  htim12.Instance = TIM12;
  htim12.Init.Prescaler = 0;
  htim12.Init.CounterMode = TIM_COUNTERMODE_UP;
  htim12.Init.Period = 24000-1;
  htim12.Init.ClockDivision = TIM_CLOCKDIVISION_DIV1;
  htim12.Init.AutoReloadPreload = TIM_AUTORELOAD_PRELOAD_ENABLE;
  if (HAL_TIM_Base_Init(&htim12) != HAL_OK)
  {
    Error_Handler();
  }
  sClockSourceConfig.ClockSource = TIM_CLOCKSOURCE_INTERNAL;
  if (HAL_TIM_ConfigClockSource(&htim12, &sClockSourceConfig) != HAL_OK)
  {
    Error_Handler();
  }
  if (HAL_TIM_PWM_Init(&htim12) != HAL_OK)
  {
    Error_Handler();
  }
  sMasterConfig.MasterOutputTrigger = TIM_TRGO_RESET;
  sMasterConfig.MasterSlaveMode = TIM_MASTERSLAVEMODE_DISABLE;
  if (HAL_TIMEx_MasterConfigSynchronization(&htim12, &sMasterConfig) != HAL_OK)
  {
    Error_Handler();
  }
  sConfigOC.OCMode = TIM_OCMODE_PWM1;
  sConfigOC.Pulse = 0;
  sConfigOC.OCPolarity = TIM_OCPOLARITY_HIGH;
  sConfigOC.OCFastMode = TIM_OCFAST_DISABLE;
  if (HAL_TIM_PWM_ConfigChannel(&htim12, &sConfigOC, TIM_CHANNEL_2) != HAL_OK)
  {
    Error_Handler();
  }
  HAL_TIM_MspPostInit(&htim12);

}

static void MX_TIM13_Init(void)
{

  TIM_OC_InitTypeDef sConfigOC = {0};

  htim13.Instance = TIM13;
  htim13.Init.Prescaler = 0;
  htim13.Init.CounterMode = TIM_COUNTERMODE_UP;
  htim13.Init.Period = 24000-1;
  htim13.Init.ClockDivision = TIM_CLOCKDIVISION_DIV1;
  htim13.Init.AutoReloadPreload = TIM_AUTORELOAD_PRELOAD_ENABLE;
  if (HAL_TIM_Base_Init(&htim13) != HAL_OK)
  {
    Error_Handler();
  }
  if (HAL_TIM_PWM_Init(&htim13) != HAL_OK)
  {
    Error_Handler();
  }
  sConfigOC.OCMode = TIM_OCMODE_PWM1;
  sConfigOC.Pulse = 0;
  sConfigOC.OCPolarity = TIM_OCPOLARITY_HIGH;
  sConfigOC.OCFastMode = TIM_OCFAST_DISABLE;
  if (HAL_TIM_PWM_ConfigChannel(&htim13, &sConfigOC, TIM_CHANNEL_1) != HAL_OK)
  {
    Error_Handler();
  }
  HAL_TIM_MspPostInit(&htim13);

}

static void MX_TIM14_Init(void)
{

  TIM_OC_InitTypeDef sConfigOC = {0};

  htim14.Instance = TIM14;
  htim14.Init.Prescaler = 0;
  htim14.Init.CounterMode = TIM_COUNTERMODE_UP;
  htim14.Init.Period = 24000-1;
  htim14.Init.ClockDivision = TIM_CLOCKDIVISION_DIV1;
  htim14.Init.AutoReloadPreload = TIM_AUTORELOAD_PRELOAD_ENABLE;
  if (HAL_TIM_Base_Init(&htim14) != HAL_OK)
  {
    Error_Handler();
  }
  if (HAL_TIM_PWM_Init(&htim14) != HAL_OK)
  {
    Error_Handler();
  }
  sConfigOC.OCMode = TIM_OCMODE_PWM1;
  sConfigOC.Pulse = 0;
  sConfigOC.OCPolarity = TIM_OCPOLARITY_HIGH;
  sConfigOC.OCFastMode = TIM_OCFAST_DISABLE;
  if (HAL_TIM_PWM_ConfigChannel(&htim14, &sConfigOC, TIM_CHANNEL_1) != HAL_OK)
  {
    Error_Handler();
  }
  HAL_TIM_MspPostInit(&htim14);

}

static void MX_TIM15_Init(void)
{

  TIM_ClockConfigTypeDef sClockSourceConfig = {0};
  TIM_MasterConfigTypeDef sMasterConfig = {0};
  TIM_OC_InitTypeDef sConfigOC = {0};
  TIM_BreakDeadTimeConfigTypeDef sBreakDeadTimeConfig = {0};

  htim15.Instance = TIM15;
  htim15.Init.Prescaler = 0;
  htim15.Init.CounterMode = TIM_COUNTERMODE_UP;
  htim15.Init.Period = 24000-1;
  htim15.Init.ClockDivision = TIM_CLOCKDIVISION_DIV1;
  htim15.Init.RepetitionCounter = 0;
  htim15.Init.AutoReloadPreload = TIM_AUTORELOAD_PRELOAD_ENABLE;
  if (HAL_TIM_Base_Init(&htim15) != HAL_OK)
  {
    Error_Handler();
  }
  sClockSourceConfig.ClockSource = TIM_CLOCKSOURCE_INTERNAL;
  if (HAL_TIM_ConfigClockSource(&htim15, &sClockSourceConfig) != HAL_OK)
  {
    Error_Handler();
  }
  if (HAL_TIM_PWM_Init(&htim15) != HAL_OK)
  {
    Error_Handler();
  }
  sMasterConfig.MasterOutputTrigger = TIM_TRGO_RESET;
  sMasterConfig.MasterSlaveMode = TIM_MASTERSLAVEMODE_DISABLE;
  if (HAL_TIMEx_MasterConfigSynchronization(&htim15, &sMasterConfig) != HAL_OK)
  {
    Error_Handler();
  }
  sConfigOC.OCMode = TIM_OCMODE_PWM1;
  sConfigOC.Pulse = 0;
  sConfigOC.OCPolarity = TIM_OCPOLARITY_HIGH;
  sConfigOC.OCNPolarity = TIM_OCNPOLARITY_HIGH;
  sConfigOC.OCFastMode = TIM_OCFAST_DISABLE;
  sConfigOC.OCIdleState = TIM_OCIDLESTATE_RESET;
  sConfigOC.OCNIdleState = TIM_OCNIDLESTATE_RESET;
  if (HAL_TIM_PWM_ConfigChannel(&htim15, &sConfigOC, TIM_CHANNEL_1) != HAL_OK)
  {
    Error_Handler();
  }
  if (HAL_TIM_PWM_ConfigChannel(&htim15, &sConfigOC, TIM_CHANNEL_2) != HAL_OK)
  {
    Error_Handler();
  }
  sBreakDeadTimeConfig.OffStateRunMode = TIM_OSSR_DISABLE;
  sBreakDeadTimeConfig.OffStateIDLEMode = TIM_OSSI_DISABLE;
  sBreakDeadTimeConfig.LockLevel = TIM_LOCKLEVEL_OFF;
  sBreakDeadTimeConfig.DeadTime = 0;
  sBreakDeadTimeConfig.BreakState = TIM_BREAK_DISABLE;
  sBreakDeadTimeConfig.BreakPolarity = TIM_BREAKPOLARITY_HIGH;
  sBreakDeadTimeConfig.BreakFilter = 0;
  sBreakDeadTimeConfig.AutomaticOutput = TIM_AUTOMATICOUTPUT_DISABLE;
  if (HAL_TIMEx_ConfigBreakDeadTime(&htim15, &sBreakDeadTimeConfig) != HAL_OK)
  {
    Error_Handler();
  }
  HAL_TIM_MspPostInit(&htim15);

}

static void MX_TIM16_Init(void)
{

  TIM_OC_InitTypeDef sConfigOC = {0};
  TIM_BreakDeadTimeConfigTypeDef sBreakDeadTimeConfig = {0};

  htim16.Instance = TIM16;
  htim16.Init.Prescaler = 0;
  htim16.Init.CounterMode = TIM_COUNTERMODE_UP;
  htim16.Init.Period = 24000-1;
  htim16.Init.ClockDivision = TIM_CLOCKDIVISION_DIV1;
  htim16.Init.RepetitionCounter = 0;
  htim16.Init.AutoReloadPreload = TIM_AUTORELOAD_PRELOAD_ENABLE;
  if (HAL_TIM_Base_Init(&htim16) != HAL_OK)
  {
    Error_Handler();
  }
  if (HAL_TIM_PWM_Init(&htim16) != HAL_OK)
  {
    Error_Handler();
  }
  sConfigOC.OCMode = TIM_OCMODE_PWM1;
  sConfigOC.Pulse = 0;
  sConfigOC.OCPolarity = TIM_OCPOLARITY_HIGH;
  sConfigOC.OCNPolarity = TIM_OCNPOLARITY_HIGH;
  sConfigOC.OCFastMode = TIM_OCFAST_DISABLE;
  sConfigOC.OCIdleState = TIM_OCIDLESTATE_RESET;
  sConfigOC.OCNIdleState = TIM_OCNIDLESTATE_RESET;
  if (HAL_TIM_PWM_ConfigChannel(&htim16, &sConfigOC, TIM_CHANNEL_1) != HAL_OK)
  {
    Error_Handler();
  }
  sBreakDeadTimeConfig.OffStateRunMode = TIM_OSSR_DISABLE;
  sBreakDeadTimeConfig.OffStateIDLEMode = TIM_OSSI_DISABLE;
  sBreakDeadTimeConfig.LockLevel = TIM_LOCKLEVEL_OFF;
  sBreakDeadTimeConfig.DeadTime = 0;
  sBreakDeadTimeConfig.BreakState = TIM_BREAK_DISABLE;
  sBreakDeadTimeConfig.BreakPolarity = TIM_BREAKPOLARITY_HIGH;
  sBreakDeadTimeConfig.BreakFilter = 0;
  sBreakDeadTimeConfig.AutomaticOutput = TIM_AUTOMATICOUTPUT_DISABLE;
  if (HAL_TIMEx_ConfigBreakDeadTime(&htim16, &sBreakDeadTimeConfig) != HAL_OK)
  {
    Error_Handler();
  }
  HAL_TIM_MspPostInit(&htim16);

}

static void MX_UART4_Init(void)
{

  huart4.Instance = UART4;
  huart4.Init.BaudRate = 115200;
  huart4.Init.WordLength = UART_WORDLENGTH_8B;
  huart4.Init.StopBits = UART_STOPBITS_1;
  huart4.Init.Parity = UART_PARITY_NONE;
  huart4.Init.Mode = UART_MODE_TX_RX;
  huart4.Init.HwFlowCtl = UART_HWCONTROL_NONE;
  huart4.Init.OverSampling = UART_OVERSAMPLING_16;
  huart4.Init.OneBitSampling = UART_ONE_BIT_SAMPLE_DISABLE;
  huart4.Init.ClockPrescaler = UART_PRESCALER_DIV1;
  huart4.AdvancedInit.AdvFeatureInit = UART_ADVFEATURE_NO_INIT;
  if (HAL_UART_Init(&huart4) != HAL_OK)
  {
    Error_Handler();
  }
  if (HAL_UARTEx_SetTxFifoThreshold(&huart4, UART_TXFIFO_THRESHOLD_1_8) != HAL_OK)
  {
    Error_Handler();
  }
  if (HAL_UARTEx_SetRxFifoThreshold(&huart4, UART_RXFIFO_THRESHOLD_1_8) != HAL_OK)
  {
    Error_Handler();
  }
  if (HAL_UARTEx_DisableFifoMode(&huart4) != HAL_OK)
  {
    Error_Handler();
  }
  /* USER CODE BEGIN UART4_Init 2 */
  UART4->CR1 |= (USART_CR1_TE|USART_CR1_RXNEIE|USART_CR1_RE|USART_CR1_UE);
  /* USER CODE END UART4_Init 2 */

}

static void MX_GPIO_Init(void)
{
  GPIO_InitTypeDef GPIO_InitStruct = {0};

  /* GPIO Ports Clock Enable */
  __HAL_RCC_GPIOE_CLK_ENABLE();
  __HAL_RCC_GPIOC_CLK_ENABLE();
  __HAL_RCC_GPIOH_CLK_ENABLE();
  __HAL_RCC_GPIOA_CLK_ENABLE();
  __HAL_RCC_GPIOB_CLK_ENABLE();
  __HAL_RCC_GPIOD_CLK_ENABLE();

  /*Configure GPIO pin Output Level */
  HAL_GPIO_WritePin(GPIOE, TIM1_CH3_PH_Pin|TIM1_CH4_PH_Pin|TIM2_CH1_PH_Pin|TIM8_CH4_PH_Pin
                          |TIM12_CH2_PH_Pin|TIM13_CH1_PH_Pin|TIM14_CH1_PH_Pin|TIM15_CH1_PH_Pin
                          |TIM1_CH1_PH_Pin|TIM1_CH2_PH_Pin, GPIO_PIN_RESET);

  /*Configure GPIO pin Output Level */
  HAL_GPIO_WritePin(GPIOC, TIM4_CH4_PH_Pin|TIM5_CH2_PH_Pin|TIM5_CH3_PH_Pin|TIM4_CH3_PH_Pin, GPIO_PIN_RESET);

  /*Configure GPIO pin Output Level */
  HAL_GPIO_WritePin(GPIOB, TIM4_CH1_PH_Pin|TIM4_CH2_PH_Pin, GPIO_PIN_RESET);

  /*Configure GPIO pin Output Level */
  HAL_GPIO_WritePin(GPIOD, HRTIM_CHC1_PH_Pin|HRTIM_CHC2_PH_Pin|HRTIM_CHD1_PH_Pin|HRTIM_CHD2_PH_Pin
                          |TIM15_CH2_PH_Pin|TIM16_CH1_PH_Pin|LPTIM1_OUT_PH_Pin|HRTIM_CHA1_PH_Pin
                          |HRTIM_CHA2_PH_Pin|HRTIM_CHB1_PH_Pin|HRTIM_CHB2_PH_Pin, GPIO_PIN_RESET);

  /*Configure GPIO pins : TIM1_CH3_PH_Pin TIM1_CH4_PH_Pin TIM2_CH1_PH_Pin TIM8_CH4_PH_Pin
                           TIM12_CH2_PH_Pin TIM13_CH1_PH_Pin TIM14_CH1_PH_Pin TIM15_CH1_PH_Pin
                           TIM1_CH1_PH_Pin TIM1_CH2_PH_Pin */
  GPIO_InitStruct.Pin = TIM1_CH3_PH_Pin|TIM1_CH4_PH_Pin|TIM2_CH1_PH_Pin|TIM8_CH4_PH_Pin
                          |TIM12_CH2_PH_Pin|TIM13_CH1_PH_Pin|TIM14_CH1_PH_Pin|TIM15_CH1_PH_Pin
                          |TIM1_CH1_PH_Pin|TIM1_CH2_PH_Pin;
  GPIO_InitStruct.Mode = GPIO_MODE_OUTPUT_PP;
  GPIO_InitStruct.Pull = GPIO_NOPULL;
  GPIO_InitStruct.Speed = GPIO_SPEED_FREQ_LOW;
  HAL_GPIO_Init(GPIOE, &GPIO_InitStruct);

  /*Configure GPIO pins : TIM4_CH4_PH_Pin TIM5_CH2_PH_Pin TIM5_CH3_PH_Pin TIM4_CH3_PH_Pin */
  GPIO_InitStruct.Pin = TIM4_CH4_PH_Pin|TIM5_CH2_PH_Pin|TIM5_CH3_PH_Pin|TIM4_CH3_PH_Pin;
  GPIO_InitStruct.Mode = GPIO_MODE_OUTPUT_PP;
  GPIO_InitStruct.Pull = GPIO_NOPULL;
  GPIO_InitStruct.Speed = GPIO_SPEED_FREQ_LOW;
  HAL_GPIO_Init(GPIOC, &GPIO_InitStruct);

  /*Configure GPIO pins : TIM4_CH1_PH_Pin TIM4_CH2_PH_Pin */
  GPIO_InitStruct.Pin = TIM4_CH1_PH_Pin|TIM4_CH2_PH_Pin;
  GPIO_InitStruct.Mode = GPIO_MODE_OUTPUT_PP;
  GPIO_InitStruct.Pull = GPIO_NOPULL;
  GPIO_InitStruct.Speed = GPIO_SPEED_FREQ_LOW;
  HAL_GPIO_Init(GPIOB, &GPIO_InitStruct);

  /*Configure GPIO pins : HRTIM_CHC1_PH_Pin HRTIM_CHC2_PH_Pin HRTIM_CHD1_PH_Pin HRTIM_CHD2_PH_Pin
                           TIM15_CH2_PH_Pin TIM16_CH1_PH_Pin LPTIM1_OUT_PH_Pin HRTIM_CHA1_PH_Pin
                           HRTIM_CHA2_PH_Pin HRTIM_CHB1_PH_Pin HRTIM_CHB2_PH_Pin */
  GPIO_InitStruct.Pin = HRTIM_CHC1_PH_Pin|HRTIM_CHC2_PH_Pin|HRTIM_CHD1_PH_Pin|HRTIM_CHD2_PH_Pin
                          |TIM15_CH2_PH_Pin|TIM16_CH1_PH_Pin|LPTIM1_OUT_PH_Pin|HRTIM_CHA1_PH_Pin
                          |HRTIM_CHA2_PH_Pin|HRTIM_CHB1_PH_Pin|HRTIM_CHB2_PH_Pin;
  GPIO_InitStruct.Mode = GPIO_MODE_OUTPUT_PP;
  GPIO_InitStruct.Pull = GPIO_NOPULL;
  GPIO_InitStruct.Speed = GPIO_SPEED_FREQ_LOW;
  HAL_GPIO_Init(GPIOD, &GPIO_InitStruct);

}

/* USER CODE BEGIN 4 */
void HAL_TIM_PeriodElapsedCallback(TIM_HandleTypeDef *htim)
{
	static int i = 0;  // index for actuator update
	static int t = 0; // variable to track time
	const int period = 10; // number of timer rollovers between updates
	const double step = 0.3;// max step size in volts

	//Used to account for period in time clicks for UART Output
		sys_timer+= 24000;

	//Used to account for period in time-scale for UART Output
		period_ticks ++;

    if (htim==&htim1){
    	t+=1;
    	if(t%period == 0)
    	{
    		if(i>=SIN_PERIOD) i = 0;
    		//update the output
    		ref = sine_vals[i]*step;
			// inform main that the actuators need an update
    		i+=1;
			ctrl_tmr_expired = TRUE;
    	}
	}

}

/*Writes commands into the circular buffer as they are sent,
once the elements is equal to the command length, a flag is sent*/
void UART_update(){
			uint8_t c;
			c = UART4->RDR;
			write_buffer(rxp, c);

			num=get_num_elements(rxp);
			if(num == CMD_LENGTH){
				cmd_ready = TRUE;
			}

	HAL_UART_Receive_IT(&huart4, rx_buff, sizeof(rx_buff));
	data_ready = FALSE;
}

/*Function that is called once the number of elements in the buffer
is equal to the command length. Fills elements into an array to print */
void command_update(){

	int n;
	n = get_num_elements(rxp);

	for(index = 0; index <= CMD_LENGTH ; index ++){
		 circ_buff_message[index] = read_from_buffer(rxp);
	 }
	HAL_UART_Transmit(&huart4, circ_buff_message, sizeof(circ_buff_message), 10);

	cmd_ready = FALSE;
}

void HAL_UART_RxCpltCallback(UART_HandleTypeDef*huart)
{
	data_ready = TRUE;
}

void HAL_UART_TxCpltCallback(UART_HandleTypeDef*huart)
{
 __NOP();
}

unsigned char get_char(void) {
    unsigned char c;
    if (is_buffer_empty(rxp) == FALSE) {
        reading_rx_buffer = TRUE; /*set buffer access flag*/
        c = read_from_buffer(rxp);
        reading_rx_buffer = FALSE;
        return c;
    }
    return 0; /*no data available*/
}

static void init_buffer(struct circular_buffer *buf) {
    int i;
    buf->read_index = 0; /*initialize read index to 0 */
    buf->write_index = 0; /*initialize write index to 0 */
    buf->size = BUFFER_LENGTH; /*Set size to buffer length const*/
    for (i = 0; i < BUFFER_LENGTH; i++) { /*initialize data to zero*/
        buf->data[i] = 0;
    } /*end for */
}

/* function int is_buffer_empty(struct circular_buffer *buf)
 * takes a pointer to a circular buffer and compares the read and write indices
 * if they are equal then the buffer is empty
 */
static int8_t is_buffer_empty(struct circular_buffer *buf) {
    if (buf->read_index == buf->write_index) { //if read = write then the buffer is empty
        return TRUE;
    }
    return FALSE;
}

/*  bufFull(struct oBuffer *buf)
 * takes a pointer to a circular buffer and compares the read and write indices
 * if write+1 = read, then the buffer is full.
 */
static int8_t is_buffer_full(struct circular_buffer *buf) {
    /* write index +1 == read index is full,  the mod provides wrap around*/
    if ((buf->write_index + 1) % BUFFER_LENGTH == buf->read_index) {
        return TRUE;
    }
    return FALSE;
}

/* writeBuffer( (struct oBuffer *buf, unsigned char c)
 * takes a pointer to a circular buffer and a char to be written
 * returns SUCCESS or ERROR
 */
static int8_t write_buffer(struct circular_buffer *buf, unsigned char c) {
    if (is_buffer_full(buf) == FALSE) {
        buf->data[buf->write_index] = c;
        /*increment the write index and wrap using modulus arithmetic */
        buf->write_index = (buf->write_index + 1) % BUFFER_LENGTH;
        return SUCCESS;
    }
    return ERROR; /*no data written*/
}

/*int readBuffer(struct oBuffer *buf)
 * takes a pointer to a circular buffer
 * returns the value from the buffer
 * the read index is incremented and wrapped using modulus arithmetic
 * Returns 0 if the buffer is empty or the pointer is invalid
 */
static unsigned char read_from_buffer(struct circular_buffer *buf) {
    unsigned char val;
    if (is_buffer_empty(buf) == FALSE) {
        val = buf->data[buf->read_index]; //get the char from the buffer
        /*increment the read index and wrap using modulus arithmetic*/
        buf->read_index = (buf->read_index + 1) % BUFFER_LENGTH;
        return val;
    }
    return 0;
}

static int get_num_elements(struct circular_buffer *buf) {
    if (buf != NULL) {
        if (buf->write_index < buf->read_index) { /*test for wrap around*/
            return (buf->write_index + BUFFER_LENGTH - buf->read_index);
        } else {
            return (buf->write_index - buf->read_index);
        }
    }
    return 0;
}

static void control_update(double ref)
{
	// sign bit of the command fed to phase input on the h-bridge
	static int phase=GPIO_PIN_SET;
	//int new_phase = {0};
	static uint16_t dutycycle=0;
	uint16_t new_dc;
	double absref = 0;

	// indicate interrupt operation
//	HAL_GPIO_TogglePin(UPDATE_GPIO_Port, UPDATE_Pin);

	// set the sign of the move (phase)
	if(ref < 0){
		phase = GPIO_PIN_RESET; // reverse direction
	} else {
		phase = GPIO_PIN_SET; //forward direction
	}
	// update the phase if it has changed
//	if(new_phase != phase){

		//Timer 1
		HAL_GPIO_WritePin(TIM1_CH1_PH_GPIO_Port, TIM1_CH1_PH_Pin, phase);  //Starts the phase generation on each of the pins (Channels)
		HAL_GPIO_WritePin(TIM1_CH2_PH_GPIO_Port, TIM1_CH2_PH_Pin, phase);
		HAL_GPIO_WritePin(TIM1_CH3_PH_GPIO_Port, TIM1_CH3_PH_Pin, phase);
		HAL_GPIO_WritePin(TIM1_CH4_PH_GPIO_Port, TIM1_CH4_PH_Pin, phase);
		//End Timer 1

		//Timer 2
		HAL_GPIO_WritePin(TIM2_CH1_PH_GPIO_Port, TIM2_CH1_PH_Pin, phase);
		//End Timer 2

		//Timer 4
		HAL_GPIO_WritePin(TIM4_CH1_PH_GPIO_Port, TIM4_CH1_PH_Pin, phase);
		HAL_GPIO_WritePin(TIM4_CH2_PH_GPIO_Port, TIM4_CH2_PH_Pin, phase);
		HAL_GPIO_WritePin(TIM4_CH3_PH_GPIO_Port, TIM4_CH3_PH_Pin, phase);
		HAL_GPIO_WritePin(TIM4_CH4_PH_GPIO_Port, TIM4_CH4_PH_Pin, phase);
		//End Timer 4

		//Timer 5
		HAL_GPIO_WritePin(TIM5_CH2_PH_GPIO_Port, TIM5_CH2_PH_Pin, phase);
		HAL_GPIO_WritePin(TIM5_CH3_PH_GPIO_Port, TIM5_CH3_PH_Pin, phase);
		//End Timer 5

		//Timer 8
		HAL_GPIO_WritePin(TIM8_CH4_PH_GPIO_Port, TIM8_CH4_PH_Pin, phase);
		//End Timer 8

		//Timer 12
		HAL_GPIO_WritePin(TIM12_CH2_PH_GPIO_Port, TIM12_CH2_PH_Pin, phase);
		//End Timer 12

		//Timer 13
		HAL_GPIO_WritePin(TIM13_CH1_PH_GPIO_Port, TIM13_CH1_PH_Pin, phase);
		//End Timer 13

		//Timer 14
		HAL_GPIO_WritePin(TIM14_CH1_PH_GPIO_Port, TIM14_CH1_PH_Pin, phase);
		//End Timer 14

		//Timer 15
		HAL_GPIO_WritePin(TIM15_CH1_PH_GPIO_Port, TIM15_CH1_PH_Pin, phase);
		HAL_GPIO_WritePin(TIM15_CH2_PH_GPIO_Port, TIM15_CH2_PH_Pin, phase);
		//End Timer 15

		//Timer 16
		HAL_GPIO_WritePin(TIM16_CH1_PH_GPIO_Port, TIM16_CH1_PH_Pin, phase);
		//End Timer 16

		//HRTIM CODE HERE **************
		//High Resolution Timer CHA
		HAL_GPIO_WritePin(HRTIM_CHA1_PH_GPIO_Port, HRTIM_CHA1_PH_Pin, phase);
		HAL_GPIO_WritePin(HRTIM_CHA2_PH_GPIO_Port, HRTIM_CHA2_PH_Pin, phase);
		//End High HRTIM CHA

		//High Resolution Timer CHB
		HAL_GPIO_WritePin(HRTIM_CHB1_PH_GPIO_Port, HRTIM_CHB1_PH_Pin, phase);
		HAL_GPIO_WritePin(HRTIM_CHB2_PH_GPIO_Port, HRTIM_CHB2_PH_Pin, phase);
		//End High HRTIM CHB

		//High Resolution Timer CHC
		HAL_GPIO_WritePin(HRTIM_CHC1_PH_GPIO_Port, HRTIM_CHC1_PH_Pin, phase);
		HAL_GPIO_WritePin(HRTIM_CHC2_PH_GPIO_Port, HRTIM_CHC2_PH_Pin, phase);
		//End High HRTIM CHC

		//High Resolution Timer CHD
		HAL_GPIO_WritePin(HRTIM_CHD1_PH_GPIO_Port, HRTIM_CHD1_PH_Pin, phase);
		HAL_GPIO_WritePin(HRTIM_CHD2_PH_GPIO_Port, HRTIM_CHD2_PH_Pin, phase);
		//End High HRTIM CHD
		//END HRTIM CODE

		//Low Power Timer
		HAL_GPIO_WritePin(LPTIM1_OUT_PH_GPIO_Port, LPTIM1_OUT_PH_Pin, phase);
		//End low power timer

//	}

	// calculate the dutycycle
	absref = fabs(ref); // duty cycle must be positive
	new_dc = calc_dutycycle(absref,VSS);
	// if new dutycycle is different than the old dutycycle
	if(new_dc != dutycycle){
		// then save new dutycycle
		dutycycle = new_dc;
		//set the new timer dutycycle register
		//Timer 1
		TIM1->CCR1 = dutycycle;   //Calls the duty cycle on the timers at the desired channel
		TIM1->CCR2 = dutycycle;
		TIM1->CCR3 = dutycycle;
		TIM1->CCR4 = dutycycle;
		//End Timer 1

		//Timer 2
		TIM2->CCR1 = dutycycle;
		//End Timer 2

		//Timer 4
		TIM4->CCR1 = dutycycle;
		TIM4->CCR2 = dutycycle;
		TIM4->CCR3 = dutycycle;
		TIM4->CCR4 = dutycycle;
		//End Timer 4

		//Timer 5
		TIM5->CCR2 = dutycycle;
		TIM5->CCR3 = dutycycle;
		//End Timer 5

		//Timer 8
		TIM8->CCR4 = dutycycle;
		//End Timer 8

		//Timer 12
		TIM12->CCR2 = dutycycle;
		//End Timer 12

		//Timer 13
		TIM13->CCR1 = dutycycle;
		//End Timer 13

		//Timer 14
		TIM14->CCR1 = dutycycle;
		//End Timer 14

		//Timer 15
		TIM15->CCR1 = dutycycle;
		TIM15->CCR2 = dutycycle;
		//End Timer 15

		//Timer 16
		TIM16->CCR1 = dutycycle;
		//End Timer 16

		//HRTIM CODE GOES HERE ********
		//HRTIM CHA
		HRTIM1->sTimerxRegs[HRTIM_TIMERINDEX_TIMER_A].CMP1xR = dutycycle;
		HRTIM1->sTimerxRegs[HRTIM_TIMERINDEX_TIMER_A].CMP2xR = dutycycle;
		//End HRTIM CHA

		//HRTIM CHB
		HRTIM1->sTimerxRegs[HRTIM_TIMERINDEX_TIMER_B].CMP1xR = dutycycle;
		HRTIM1->sTimerxRegs[HRTIM_TIMERINDEX_TIMER_B].CMP2xR = dutycycle;
		//End HRTIM CHB

		//HRTIM CHC
		HRTIM1->sTimerxRegs[HRTIM_TIMERINDEX_TIMER_C].CMP1xR = dutycycle;
		HRTIM1->sTimerxRegs[HRTIM_TIMERINDEX_TIMER_C].CMP2xR = dutycycle;
		//End HRTIM CHC

		//HRTIM CHD
		HRTIM1->sTimerxRegs[HRTIM_TIMERINDEX_TIMER_D].CMP1xR = dutycycle;
		HRTIM1->sTimerxRegs[HRTIM_TIMERINDEX_TIMER_D].CMP2xR = dutycycle;
		//End HRTIM CHD
		//END HRTIM CODE HERE

		//LPTIM1
		LPTIM1->CMP = dutycycle/2;
		//End LPTIM1

	}

	// reset timer flag
	ctrl_tmr_expired = FALSE;
}

static uint16_t calc_dutycycle(double cmd, double vss)
{
	//------------------------------//
	//	@function calc_dutycycle(cmd, vss)
	//	@ param cmd command voltage
	//	@ param vss supply voltage
	//	@ return dutycycle

	// duty cycle variable
	uint16_t dc={0};

	dc = (uint16_t)(cmd/vss * (double)PERIOD);
	// keep the dutycycle within the period of the PWM signal
	if(dc>PERIOD) dc = PERIOD;

	return dc;
}

static void gen_sine(void)
{
	int i = 0;
	double scale = TWO_PI/SIN_PERIOD;
	for(i=0; i<SIN_PERIOD; i++ )
	{
		sine_vals[i] = sin(i*scale);
	}
}

/* USER CODE END 4 */

 /* MPU Configuration */

void MPU_Config(void)
{
  MPU_Region_InitTypeDef MPU_InitStruct = {0};

  /* Disables the MPU */
  HAL_MPU_Disable();

  /** Initializes and configures the Region and the memory to be protected
  */
  MPU_InitStruct.Enable = MPU_REGION_ENABLE;
  MPU_InitStruct.Number = MPU_REGION_NUMBER0;
  MPU_InitStruct.BaseAddress = 0x0;
  MPU_InitStruct.Size = MPU_REGION_SIZE_4GB;
  MPU_InitStruct.SubRegionDisable = 0x87;
  MPU_InitStruct.TypeExtField = MPU_TEX_LEVEL0;
  MPU_InitStruct.AccessPermission = MPU_REGION_NO_ACCESS;
  MPU_InitStruct.DisableExec = MPU_INSTRUCTION_ACCESS_DISABLE;
  MPU_InitStruct.IsShareable = MPU_ACCESS_SHAREABLE;
  MPU_InitStruct.IsCacheable = MPU_ACCESS_NOT_CACHEABLE;
  MPU_InitStruct.IsBufferable = MPU_ACCESS_NOT_BUFFERABLE;

  HAL_MPU_ConfigRegion(&MPU_InitStruct);
  /* Enables the MPU */
  HAL_MPU_Enable(MPU_PRIVILEGED_DEFAULT);

}

void Error_Handler(void)
{
  __disable_irq();
  while (1)
  {
  }
}

>>>>>>> main
